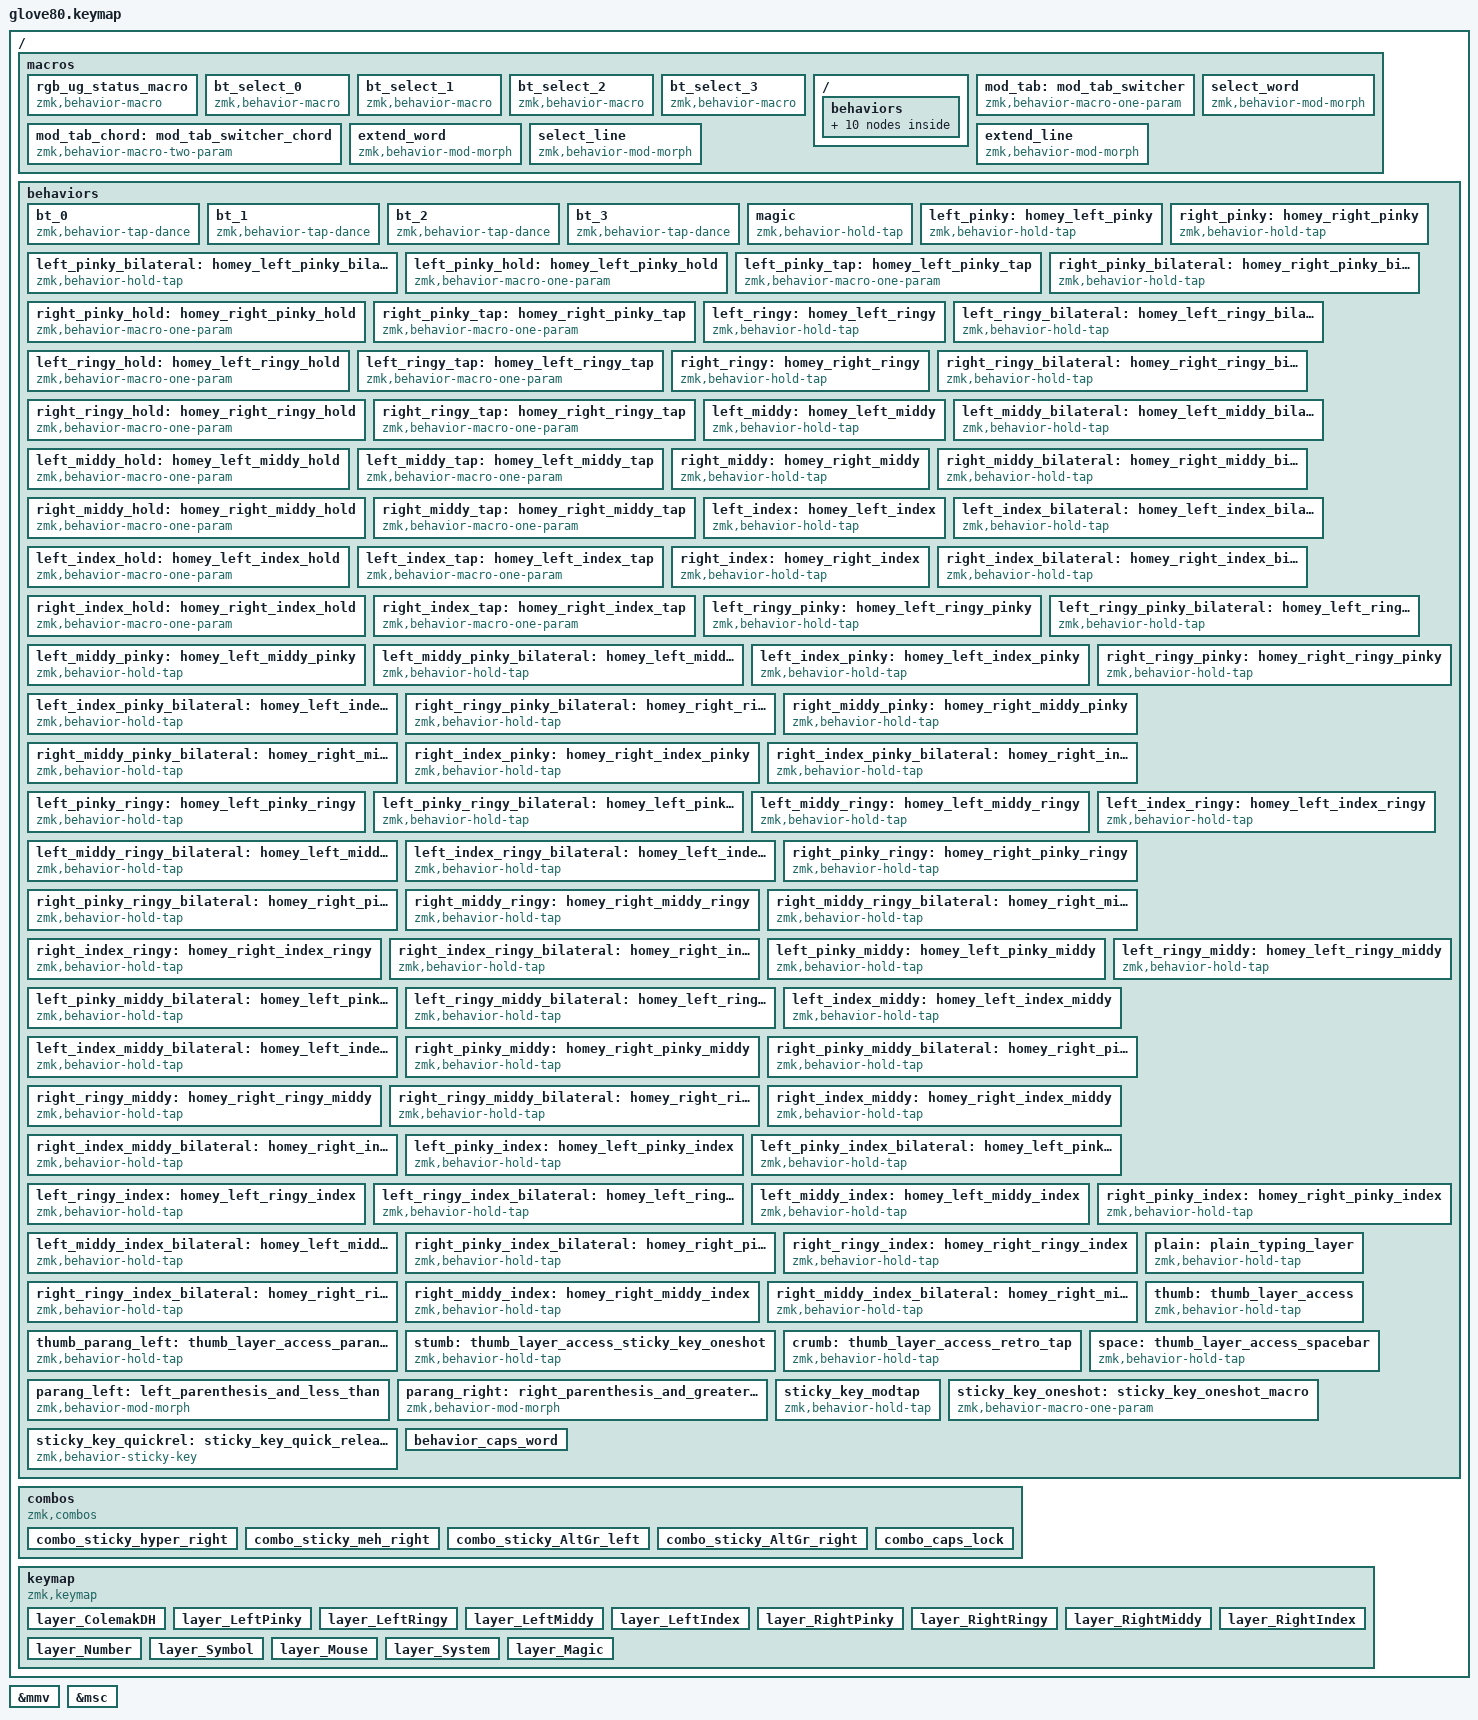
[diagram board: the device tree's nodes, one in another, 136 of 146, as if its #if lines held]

/*
 * Copyright (c) 2020 The ZMK Contributors
 * Copyright (c) 2023 Innaworks Development Limited, trading as MoErgo
 *
 * SPDX-License-Identifier: MIT
 */


/* THIS FILE WAS GENERATED BY GLOVE80 LAYOUT EDITOR
 *
 * This file was generated automatically. You may or may not want to
 * edit it directly.
 */

#include <behaviors.dtsi>
/* Include all behavior includes needed */
#include <dt-bindings/zmk/outputs.h>
#include <dt-bindings/zmk/keys.h>
#include <dt-bindings/zmk/bt.h>
#include <dt-bindings/zmk/rgb.h>

/* Automatically generated layer name #define */
#define LAYER_ColemakDH 0
#define LAYER_LeftPinky 1
#define LAYER_LeftRingy 2
#define LAYER_LeftMiddy 3
#define LAYER_LeftIndex 4
#define LAYER_RightPinky 5
#define LAYER_RightRingy 6
#define LAYER_RightMiddy 7
#define LAYER_RightIndex 8
#define LAYER_Number 9
#define LAYER_Symbol 10
#define LAYER_Mouse 11
#define LAYER_System 12
#define LAYER_Magic 13

/* Custom Device-tree */
//////////////////////////////////////////////////////////////////////////
//
// Mouse keys (keyboard mouse control) requires v24.12 firmware or newer:
// override the "HID_POINTING" setting to "y" in Advanced Configuration
// and then select "v24.12" firmware from the drop-down menu located at
// Glove80 Layout Editor > Settings > Advanced Settings > Firmware Version
//
// Alternatively, you can still use the older PR23 beta firmware for this:
// select "community.pr23.mouse-keys" from the drop-down menu located at
// Glove80 Layout Editor > Settings > Advanced Settings > Firmware Version
//
// - https://github.com/moergo-sc/zmk/pull/23
// - https://gist.github.com/krissen/dd27082e7ab0575619c7a31f4d2ec7ae
// - https://github.com/zmkfirmware/zmk/compare/main...urob:zmk:mouse-3.2
//
//////////////////////////////////////////////////////////////////////////

//
// MOUSE_MOTION_DELAY defines how long to wait (milliseconds) before starting
// to move the mouse pointer.
//
#ifndef MOUSE_MOTION_DELAY
#define MOUSE_MOTION_DELAY 0
#endif

//
// MOUSE_MOTION_ACCELERATION_EXPONENT sets how the mouse pointer accelerates:
//
// acceleration exponent 0: uniform speed
// acceleration exponent 1: uniform acceleration
// acceleration exponent 2: uniform jerk
//
#ifndef MOUSE_MOTION_ACCELERATION_EXPONENT
#define MOUSE_MOTION_ACCELERATION_EXPONENT 1
#endif

//
// MOUSE_MOTION_TIME_TO_MAXIMUM_SPEED defines how long to wait (milliseconds)
// before the mouse pointer speed is suddenly boosted to the maximum value.
//
#ifndef MOUSE_MOTION_TIME_TO_MAXIMUM_SPEED
#define MOUSE_MOTION_TIME_TO_MAXIMUM_SPEED 300
#endif

//
// MOUSE_MOTION_MAXIMUM_SPEED defines how quickly the mouse pointer can move.
//
#ifndef MOUSE_MOTION_MAXIMUM_SPEED
#define MOUSE_MOTION_MAXIMUM_SPEED 600
#endif

//
// MOUSE_SCROLL_DELAY defines how long to wait (milliseconds) before starting
// to move the mouse pointer.
//
#ifndef MOUSE_SCROLL_DELAY
#define MOUSE_SCROLL_DELAY 0
#endif

//
// MOUSE_SCROLL_ACCELERATION_EXPONENT sets how the mouse pointer accelerates:
//
// acceleration exponent 0: uniform speed
// acceleration exponent 1: uniform acceleration
// acceleration exponent 2: uniform jerk
//
#ifndef MOUSE_SCROLL_ACCELERATION_EXPONENT
#define MOUSE_SCROLL_ACCELERATION_EXPONENT 0
#endif

//
// MOUSE_SCROLL_TIME_TO_MAXIMUM_SPEED defines how long to wait (milliseconds)
// before the mouse pointer speed is suddenly boosted to the maximum value.
//
#ifndef MOUSE_SCROLL_TIME_TO_MAXIMUM_SPEED
#define MOUSE_SCROLL_TIME_TO_MAXIMUM_SPEED 300
#endif

//
// MOUSE_SCROLL_MAXIMUM_SPEED defines how quickly the mouse wheel can scroll.
//
#ifndef MOUSE_SCROLL_MAXIMUM_SPEED
#define MOUSE_SCROLL_MAXIMUM_SPEED 10
#endif

#if __has_include(<zmk/events/mouse_tick.h>) || ( \
  defined(MOERGO_FIRMWARE_VERSION_MAJOR) &&       \
  defined(MOERGO_FIRMWARE_VERSION_MINOR) && (     \
    MOERGO_FIRMWARE_VERSION_MAJOR == 24 &&        \
    MOERGO_FIRMWARE_VERSION_MINOR == 12 ||        \
    MOERGO_FIRMWARE_VERSION_MAJOR > 24            \
  )                                               \
)
  // ==== MOUSE-KEY <section begins> ====
  #define ZMK_MOUSE_DEFAULT_MOVE_VAL MOUSE_MOTION_MAXIMUM_SPEED
  #define ZMK_MOUSE_DEFAULT_SCRL_VAL MOUSE_SCROLL_MAXIMUM_SPEED
  #include <dt-bindings/zmk/mouse.h>
  &mmv {
    delay-ms = <MOUSE_MOTION_DELAY>;
    acceleration-exponent = <MOUSE_MOTION_ACCELERATION_EXPONENT>;
    time-to-max-speed-ms = <MOUSE_MOTION_TIME_TO_MAXIMUM_SPEED>;
  };
  &msc {
    delay-ms = <MOUSE_SCROLL_DELAY>;
    acceleration-exponent = <MOUSE_SCROLL_ACCELERATION_EXPONENT>;
    time-to-max-speed-ms = <MOUSE_SCROLL_TIME_TO_MAXIMUM_SPEED>;
  };
  // ==== MOUSE-KEY <section ends> =====
#else
  #define mkp none
  #define mmv none
  #define msc none
  #define LCLK
  #define MCLK
  #define RCLK
  #define MB1
  #define MB2
  #define MB3
  #define MB4
  #define MB5
  #define MB6
  #define MB7
  #define MB8
  #define MOVE_UP
  #define MOVE_DOWN
  #define MOVE_LEFT
  #define MOVE_RIGHT
  #define SCRL_UP
  #define SCRL_DOWN
  #define SCRL_LEFT
  #define SCRL_RIGHT
#endif

/ {
    macros {
        rgb_ug_status_macro: rgb_ug_status_macro {
            label = "RGB_UG_STATUS";
            compatible = "zmk,behavior-macro";
            #binding-cells = <0>;
            bindings
                = <&rgb_ug RGB_STATUS>;
        };
    };
};


/ {
#ifdef BT_DISC_CMD
    behaviors {
        bt_0: bt_0 {
            compatible = "zmk,behavior-tap-dance";
            label = "BT_0";
            #binding-cells = <0>;
            tapping-term-ms = <200>;
            bindings = <&bt_select_0>, <&bt BT_DISC 0>;
        };
        bt_1: bt_1 {
            compatible = "zmk,behavior-tap-dance";
            label = "BT_1";
            #binding-cells = <0>;
            tapping-term-ms = <200>;
            bindings = <&bt_select_1>, <&bt BT_DISC 1>;
        };
        bt_2: bt_2 {
            compatible = "zmk,behavior-tap-dance";
            label = "BT_2";
            #binding-cells = <0>;
            tapping-term-ms = <200>;
            bindings = <&bt_select_2>, <&bt BT_DISC 2>;
        };
        bt_3: bt_3 {
            compatible = "zmk,behavior-tap-dance";
            label = "BT_3";
            #binding-cells = <0>;
            tapping-term-ms = <200>;
            bindings = <&bt_select_3>, <&bt BT_DISC 3>;
        };
    };
    macros {
        bt_select_0: bt_select_0 {
            label = "BT_SELECT_0";
            compatible = "zmk,behavior-macro";
            #binding-cells = <0>;
            bindings
                = <&out OUT_BLE>,
                  <&bt BT_SEL 0>;
        };
        bt_select_1: bt_select_1 {
            label = "BT_SELECT_1";
            compatible = "zmk,behavior-macro";
            #binding-cells = <0>;
            bindings
                = <&out OUT_BLE>,
                  <&bt BT_SEL 1>;
        };
        bt_select_2: bt_select_2 {
            label = "BT_SELECT_2";
            compatible = "zmk,behavior-macro";
            #binding-cells = <0>;
            bindings
                = <&out OUT_BLE>,
                  <&bt BT_SEL 2>;
        };
        bt_select_3: bt_select_3 {
            label = "BT_SELECT_3";
            compatible = "zmk,behavior-macro";
            #binding-cells = <0>;
            bindings
                = <&out OUT_BLE>,
                  <&bt BT_SEL 3>;
        };
    };
#else
    macros {
        bt_0: bt_0 {
            label = "BT_0";
            compatible = "zmk,behavior-macro";
            #binding-cells = <0>;
            bindings
                = <&out OUT_BLE>,
                  <&bt BT_SEL 0>;
        };
        bt_1: bt_1 {
            label = "BT_1";
            compatible = "zmk,behavior-macro";
            #binding-cells = <0>;
            bindings
                = <&out OUT_BLE>,
                  <&bt BT_SEL 1>;
        };
        bt_2: bt_2 {
            label = "BT_2";
            compatible = "zmk,behavior-macro";
            #binding-cells = <0>;
            bindings
                = <&out OUT_BLE>,
                  <&bt BT_SEL 2>;
        };
        bt_3: bt_3 {
            label = "BT_3";
            compatible = "zmk,behavior-macro";
            #binding-cells = <0>;
            bindings
                = <&out OUT_BLE>,
                  <&bt BT_SEL 3>;
        };
    };
#endif
};

/ {
    behaviors {
        magic: magic {
            compatible = "zmk,behavior-hold-tap";
            label = "MAGIC_HOLD_TAP";
            #binding-cells = <2>;
            flavor = "tap-preferred";
            tapping-term-ms = <200>;
            bindings = <&mo>, <&rgb_ug_status_macro>;
        };
    };
};

/* #define for key positions */
#define POS_LH_T1 52
#define POS_LH_T2 53
#define POS_LH_T3 54
#define POS_LH_T4 69
#define POS_LH_T5 70
#define POS_LH_T6 71
#define POS_LH_C1R2 15
#define POS_LH_C1R3 27
#define POS_LH_C1R4 39
#define POS_LH_C1R5 51
#define POS_LH_C2R1 4
#define POS_LH_C2R2 14
#define POS_LH_C2R3 26
#define POS_LH_C2R4 38
#define POS_LH_C2R5 50
#define POS_LH_C2R6 68
#define POS_LH_C3R1 3
#define POS_LH_C3R2 13
#define POS_LH_C3R3 25
#define POS_LH_C3R4 37
#define POS_LH_C3R5 49
#define POS_LH_C3R6 67
#define POS_LH_C4R1 2
#define POS_LH_C4R2 12
#define POS_LH_C4R3 24
#define POS_LH_C4R4 36
#define POS_LH_C4R5 48
#define POS_LH_C4R6 66
#define POS_LH_C5R1 1
#define POS_LH_C5R2 11
#define POS_LH_C5R3 23
#define POS_LH_C5R4 35
#define POS_LH_C5R5 47
#define POS_LH_C5R6 65
#define POS_LH_C6R1 0
#define POS_LH_C6R2 10
#define POS_LH_C6R3 22
#define POS_LH_C6R4 34
#define POS_LH_C6R5 46
#define POS_LH_C6R6 64
#define POS_RH_T1 57
#define POS_RH_T2 56
#define POS_RH_T3 55
#define POS_RH_T4 74
#define POS_RH_T5 73
#define POS_RH_T6 72
#define POS_RH_C1R2 16
#define POS_RH_C1R3 28
#define POS_RH_C1R4 40
#define POS_RH_C1R5 58
#define POS_RH_C2R1 5
#define POS_RH_C2R2 17
#define POS_RH_C2R3 29
#define POS_RH_C2R4 41
#define POS_RH_C2R5 59
#define POS_RH_C2R6 75
#define POS_RH_C3R1 6
#define POS_RH_C3R2 18
#define POS_RH_C3R3 30
#define POS_RH_C3R4 42
#define POS_RH_C3R5 60
#define POS_RH_C3R6 76
#define POS_RH_C4R1 7
#define POS_RH_C4R2 19
#define POS_RH_C4R3 31
#define POS_RH_C4R4 43
#define POS_RH_C4R5 61
#define POS_RH_C4R6 77
#define POS_RH_C5R1 8
#define POS_RH_C5R2 20
#define POS_RH_C5R3 32
#define POS_RH_C5R4 44
#define POS_RH_C5R5 62
#define POS_RH_C5R6 78
#define POS_RH_C6R1 9
#define POS_RH_C6R2 21
#define POS_RH_C6R3 33
#define POS_RH_C6R4 45
#define POS_RH_C6R5 63
#define POS_RH_C6R6 79

/* Custom Defined Behaviors */
/ {
// NOTE: Use the many #define settings below to customize this keymap!
#define OPERATING_SYSTEM 'L' // choose 'L'inux, 'M'acOS, or 'W'indows
#define ENFORCE_BILATERAL    // cancels single-handed home row mod+tap
#define SPACE_FORGIVENESS    // allow lingering taps on the space bar
//#define THUMB_FORGIVENESS  // allow lingering taps on the thumb keys
//#define SHIFT_FORGIVENESS  // requires 24.08-beta1 or newer firmware
#define WORLD_USE_COMPOSE    // use native Compose in place of Unicode
//#define WORLD_HOST_AZERTY  // host computer is set to AZERTY locale
//#define WORLD_SHIFT_NUMBER // apply Shift to type number row digits
// TIP: Add more setting overrides here instead of editing them below.

//////////////////////////////////////////////////////////////////////////////
//
// Sunaku's Keymap v40 -- "Glorious Engrammer"
// - https://github.com/sunaku/glove80-keymaps
//
//////////////////////////////////////////////////////////////////////////////

//
// OPERATING_SYSTEM defines which operating system you intend to use
// with this keymap, because shortcuts vary across operating systems.
//
// - https://zmk.dev/docs/codes
// - https://en.wikipedia.org/wiki/Table_of_keyboard_shortcuts
//
// This setting also affects the UNICODE() function defined below, as
// each OS has different shortcuts for typing Unicode hex characters.
//
// NOTE: You may need to enable Unicode hexadecimal input in your OS:
// - (macOS) https://uknowit.uwgb.edu/page.php?id=22623
//     and   https://github.com/ldanet/unicode-hex-input-fix
// - (Linux) https://help.ubuntu.com/stable/ubuntu-help/tips-specialchars.html.en#ctrlshiftu
// - (Windows) https://github.com/samhocevar/wincompose
//
// Specifically, Windows users should be running the WinCompose tool,
// which lets you type Unicode characters via hexadecimal codepoints.
//
#ifndef OPERATING_SYSTEM
#define OPERATING_SYSTEM 'L' // linux
//#define OPERATING_SYSTEM 'M' // macos
//#define OPERATING_SYSTEM 'W' // windows
#endif
#if OPERATING_SYSTEM == 'M'
  #define _C      LG
  #define _A_TAB  LGUI
  #define _G_TAB  LALT
  #define _REDO   _C(LS(Z))
  #define _POWER  K_POWER
  #define _W      LA
  #define _HOME   _C(LEFT)
  #define _END    _C(RIGHT)
#else
  #define _C      LC
  #define _A_TAB  LALT
  #define _G_TAB  LGUI
  #define _REDO   _C(Y)
  #define _POWER  C_POWER
  #define _W      _C
  #define _HOME   HOME
  #define _END    END
#endif
#define _SLEEP      C_SLEEP
#if OPERATING_SYSTEM == 'W'
  #define _LOCK   LG(L)
#elif OPERATING_SYSTEM == 'M'
  #define _LOCK   _C(LC(Q))
#elif OPERATING_SYSTEM == 'L'
  #define _LOCK   K_LOCK
#endif
#define _UNDO       _C(Z)
#define _CUT        _C(X)
#define _COPY       _C(C)
#define _PASTE      _C(V)
#define _FIND       _C(F)
#define _FIND_NEXT  _C(G)
#define _FIND_PREV  _C(LS(G))

//
// USE_NUMPAD_KEYCODES puts `KP_*` keycodes into the Number layer.
//
#ifdef USE_NUMPAD_KEYCODES
#define _KP_N0 KP_N0
#define _KP_N1 KP_N1
#define _KP_N2 KP_N2
#define _KP_N3 KP_N3
#define _KP_N4 KP_N4
#define _KP_N5 KP_N5
#define _KP_N6 KP_N6
#define _KP_N7 KP_N7
#define _KP_N8 KP_N8
#define _KP_N9 KP_N9
#define _KP_PLUS KP_PLUS
#define _KP_MINUS KP_MINUS
#define _KP_ASTERISK KP_ASTERISK
#define _KP_SLASH KP_SLASH
#define _KP_COMMA KP_COMMA
#define _KP_DOT KP_DOT
#define _KP_EQUAL KP_EQUAL
#define _KP_ENTER KP_ENTER
#else
#define _KP_N0 N0
#define _KP_N1 N1
#define _KP_N2 N2
#define _KP_N3 N3
#define _KP_N4 N4
#define _KP_N5 N5
#define _KP_N6 N6
#define _KP_N7 N7
#define _KP_N8 N8
#define _KP_N9 N9
#define _KP_PLUS PLUS
#define _KP_MINUS MINUS
#define _KP_ASTERISK ASTERISK
#define _KP_SLASH SLASH
#define _KP_COMMA COMMA
#define _KP_DOT DOT
#define _KP_EQUAL EQUAL
#define _KP_ENTER ENTER
#endif

//
// Keymap specific knowledge of the base layer's alpha + ZMK layout
//
#if defined(LAYER_ColemakDH) && LAYER_ColemakDH == 0
#define KEY_LH_C6R1 UP
#define KEY_LH_C5R1 DOWN
#define KEY_LH_C4R1 A
#define KEY_LH_C3R1 B
#define KEY_LH_C2R1 C
#define KEY_RH_C2R1 D
#define KEY_RH_C3R1 E
#define KEY_RH_C4R1 F
#define KEY_RH_C5R1 LEFT
#define KEY_RH_C6R1 RIGHT
#define KEY_LH_C6R2 EQUAL
#define KEY_LH_C5R2 N1
#define KEY_LH_C4R2 N2
#define KEY_LH_C3R2 N3
#define KEY_LH_C2R2 N4
#define KEY_LH_C1R2 N5
#define KEY_RH_C1R2 N6
#define KEY_RH_C2R2 N7
#define KEY_RH_C3R2 N8
#define KEY_RH_C4R2 N9
#define KEY_RH_C5R2 N0
#define KEY_RH_C6R2 MINUS
#define KEY_LH_C6R3 GRAVE
#define KEY_LH_C5R3 Q
#define KEY_LH_C4R3 W
#define KEY_LH_C3R3 F
#define KEY_LH_C2R3 P
#define KEY_LH_C1R3 B
#define KEY_RH_C1R3 J
#define KEY_RH_C2R3 L
#define KEY_RH_C3R3 U
#define KEY_RH_C4R3 Y
#define KEY_RH_C5R3 SEMI
#define KEY_RH_C6R3 BSLH
#define KEY_LH_C6R4 CAPS
#define KEY_LH_C5R4 A
#define KEY_LH_C4R4 R
#define KEY_LH_C3R4 S
#define KEY_LH_C2R4 T
#define KEY_LH_C1R4 G
#define KEY_RH_C1R4 M
#define KEY_RH_C2R4 N
#define KEY_RH_C3R4 E
#define KEY_RH_C4R4 I
#define KEY_RH_C5R4 O
#define KEY_RH_C6R4 SQT
#define KEY_LH_C6R5 LSFT
#define KEY_LH_C5R5 Z
#define KEY_LH_C4R5 X
#define KEY_LH_C3R5 C
#define KEY_LH_C2R5 D
#define KEY_LH_C1R5 V
#define KEY_LH_T1 ESC
#define KEY_LH_T2 LSFT
#define KEY_LH_T3 0
#define KEY_RH_T3 0
#define KEY_RH_T2 RSFT
#define KEY_RH_T1 ENTER
#define KEY_RH_C1R5 K
#define KEY_RH_C2R5 H
#define KEY_RH_C3R5 COMMA
#define KEY_RH_C4R5 DOT
#define KEY_RH_C5R5 FSLH
#define KEY_RH_C6R5 RSFT
#define KEY_LH_C6R6 0
#define KEY_LH_C5R6 HOME
#define KEY_LH_C4R6 PG_UP
#define KEY_LH_C3R6 PG_DN
#define KEY_LH_C2R6 END
#define KEY_LH_T4 BACKSPACE
#define KEY_LH_T5 DELETE
#define KEY_LH_T6 0
#define KEY_RH_T6 0
#define KEY_RH_T5 TAB
#define KEY_RH_T4 SPACE
#define KEY_RH_C2R6 LPAR
#define KEY_RH_C3R6 LBKT
#define KEY_RH_C4R6 RBKT
#define KEY_RH_C5R6 RPAR
#define KEY_RH_C6R6 0
#endif

combos {
  compatible = "zmk,combos";

  //
  // COMBO_FIRING_DECAY defines how much time you have left (milliseconds)
  // after pressing the first key in a ZMK combo to finish the whole chord.
  //
  #ifndef COMBO_FIRING_DECAY
  #define COMBO_FIRING_DECAY 50
  #endif

  combo_sticky_hyper_right {
    timeout-ms = <COMBO_FIRING_DECAY>;
    key-positions = <POS_RH_T1 POS_RH_T4>;
    bindings = <&sk LG(LA(LC(LSHFT)))>;
    layers = <0 1 2 3 4 5 6 7 8 9 10>;
  };

  combo_sticky_meh_right {
    timeout-ms = <COMBO_FIRING_DECAY>;
    key-positions = <POS_RH_T4 POS_RH_T5>;
    bindings = <&sk LA(LC(LSHFT))>;
    layers = <0 1 2 3 4 5 6 7 8 9 10>;
  };

  combo_sticky_AltGr_left {
    timeout-ms = <COMBO_FIRING_DECAY>;
    key-positions = <POS_LH_T2 POS_LH_T5>;
    bindings = <&sk RALT>;
    layers = <0 1 2 3 4 5 6 7 8 9 10>;
  };

  combo_sticky_AltGr_right {
    timeout-ms = <COMBO_FIRING_DECAY>;
    key-positions = <POS_RH_T2 POS_RH_T5>;
    bindings = <&sk RALT>;
    layers = <0 1 2 3 4 5 6 7 8 9 10>;
  };

  combo_caps_lock {
    timeout-ms = <COMBO_FIRING_DECAY>;
    key-positions = <POS_LH_T6 POS_RH_T6>;
    bindings = <&kp CAPSLOCK>;
    layers = <0 1 2 3 4 5 6 7 8 9 10>;
  };

};

behaviors {

  //////////////////////////////////////////////////////////////////////////
  //
  // Miryoku layers and home row mods (ported from my QMK endgame)
  // - https://sunaku.github.io/home-row-mods.html#porting-to-zmk
  // - https://github.com/urob/zmk-config#timeless-homerow-mods
  //
  //////////////////////////////////////////////////////////////////////////

  //
  // TAPPING_RESOLUTION specifies the maximum speed at which the keyboard
  // confuses your taps as being holds when you type on home row mod keys.
  // When you lower this value, the same confusion should still occur; but
  // when you raise this value, you should be able to type normally again.
  //
  #ifndef TAPPING_RESOLUTION
  #define TAPPING_RESOLUTION 150
  #endif

  //
  // ENFORCE_BILATERAL cancels out single-handed home row mods activation by
  // releasing any currently pressed mods and replacing them with plain taps.
  //
  // NOTE: You may still encounter "flashing mods" where an operating system
  // action is triggered by the release of mods, such as LGUI which launches
  // the Windows Start Menu and LALT which opens the Microsoft Office Ribbon.
  //
  //#define ENFORCE_BILATERAL

  //
  // SHIFT_FORGIVENESS taps when home row shift is merely held and released,
  // without any other key having been tapped while the shift was held down.
  // For example, suppose you hold a home row shift key and, before pressing
  // another key, you suddenly decide that you don't want the shift anymore:
  //
  // <1> If this setting is enabled, the underlying tap behavior is triggered
  //     to type a single character when you release that home row shift key.
  //
  // <2> Otherwise, nothing happens when you release that home row shift key.
  //
  // This requires the "hold-while-undecided" ZMK feature in a beta firmware:
  // please select "v24.08-beta1" or newer from the drop-down menu located at
  // Glove80 Layout Editor > Settings > Advanced Settings > Firmware Version.
  //
  // CAUTION: This can interfere with mod-click mouse usage where you hold a
  // home row shift key and perform mouse actions (move, click, drag & drop):
  // when you release that home row shift key, its underlying character would
  // be typed, potentially triggering an unexpected action on your selection!
  // To prevent the underlying character from being typed, press another key
  // (such as a dedicated shift key, a neighboring home row mod key, or even
  // a layer access key) before you release the original home row shift key.
  //
  // NOTE: You may potentially encounter "flashing mods" where an application
  // or operating system action is triggered by a standalone tap of a shift,
  // but this is unlikely as people regularly tap shift without consequence.
  //
  //#define SHIFT_FORGIVENESS

  //
  // THUMB_FORGIVENESS taps when a thumb layer access key is merely held and
  // released, without any other key having been tapped while thumb was held.
  // For example, suppose you hold the cursor layer key and, before pressing
  // another key, you suddenly decide that you don't want the layer anymore:
  //
  // <1> If this setting is enabled, the underlying tap behavior is triggered
  //     to type a single character when you release that layer access key.
  //
  // <2> Otherwise, nothing happens when you release that layer access key.
  //
  // NOTE: This setting interferes with (and effectively disables) per-key
  // RGB indicators (PR30) for layers accessed via thumb layer access keys.
  //
  //#define THUMB_FORGIVENESS

  //
  // SPACE_FORGIVENESS taps when the symbol layer access key is merely held
  // and released, without any symbol been tapped while the access was held.
  // For example, suppose you hold the symbol layer key and, before pressing
  // another key, you suddenly decide that you don't want the layer anymore:
  //
  // <1> If this setting is enabled, the underlying tap behavior is triggered
  //     to type a single character when you release that layer access key.
  //
  // <2> Otherwise, nothing happens when you release that layer access key.
  //
  // NOTE: This setting interferes with (and effectively disables) per-key
  // RGB indicators (PR30) for layers accessed via thumb layer access keys.
  //
  //#define SPACE_FORGIVENESS

  //
  // The *_FINGER_MOD specify which modifiers are used by home row mod keys.
  // Here, we use Miryoku's "GACS" (Win, Alt, Ctrl, Shift) order by default,
  // unless OPERATING_SYSTEM is macOS, in which case Win & Ctrl are swapped,
  // unless MACOS_USE_GACS is also defined to suppress that Win & Ctrl swap.
  //
  #ifndef PINKY_FINGER_MOD
    #if OPERATING_SYSTEM == 'M' && !defined(MACOS_USE_GACS)
      #define PINKY_FINGER_MOD LCTL
    #else
      #define PINKY_FINGER_MOD LGUI
    #endif
  #endif
  #ifndef RINGY_FINGER_MOD
  #define RINGY_FINGER_MOD LALT
  #endif
  #ifndef MIDDY_FINGER_MOD
    #if OPERATING_SYSTEM == 'M' && !defined(MACOS_USE_GACS)
      #define MIDDY_FINGER_MOD LGUI
    #else
      #define MIDDY_FINGER_MOD LCTL
    #endif
  #endif
  #ifndef INDEX_FINGER_MOD
  #define INDEX_FINGER_MOD LSFT
  #endif
  //
  // The following settings let you configure mods individually, per finger:
  //
  #ifndef LEFT_PINKY_MOD
  #define LEFT_PINKY_MOD PINKY_FINGER_MOD
  #endif
  #ifndef RIGHT_PINKY_MOD
  #define RIGHT_PINKY_MOD PINKY_FINGER_MOD
  #endif
  #ifndef LEFT_RINGY_MOD
  #define LEFT_RINGY_MOD RINGY_FINGER_MOD
  #endif
  #ifndef RIGHT_RINGY_MOD
  #define RIGHT_RINGY_MOD RINGY_FINGER_MOD
  #endif
  #ifndef LEFT_MIDDY_MOD
  #define LEFT_MIDDY_MOD MIDDY_FINGER_MOD
  #endif
  #ifndef RIGHT_MIDDY_MOD
  #define RIGHT_MIDDY_MOD MIDDY_FINGER_MOD
  #endif
  #ifndef LEFT_INDEX_MOD
  #define LEFT_INDEX_MOD INDEX_FINGER_MOD
  #endif
  #ifndef RIGHT_INDEX_MOD
  #define RIGHT_INDEX_MOD INDEX_FINGER_MOD
  #endif

  //
  // HOMEY_HOLDING_TYPE defines the flavor of ZMK hold-tap behavior to use
  // for the pinky, ring, and middle fingers (which are assigned to Super,
  // Alt, and Ctrl respectively in the Miryoku system) on home row keys.
  //
  #ifndef HOMEY_HOLDING_TYPE
  #define HOMEY_HOLDING_TYPE "tap-preferred"
  #endif

  //
  // HOMEY_HOLDING_TIME defines how long you need to hold (milliseconds)
  // home row mod keys in order to send their modifiers to the computer
  // (i.e. "register" them) for mod-click mouse usage (e.g. Ctrl-Click).
  //
  #ifndef HOMEY_HOLDING_TIME
  #define HOMEY_HOLDING_TIME (TAPPING_RESOLUTION + 90)
  #endif
  #ifndef INDEX_HOLDING_TIME
  #define INDEX_HOLDING_TIME (TAPPING_RESOLUTION + 20)
  #endif
  #ifndef MIDDY_HOLDING_TIME
  #define MIDDY_HOLDING_TIME (TAPPING_RESOLUTION + 60)
  #endif
  #ifndef RINGY_HOLDING_TIME
  #define RINGY_HOLDING_TIME (TAPPING_RESOLUTION + 90)
  #endif
  #ifndef PINKY_HOLDING_TIME
  #define PINKY_HOLDING_TIME (TAPPING_RESOLUTION + 110)
  #endif

  //
  // HOMEY_STREAK_DECAY defines how long you need to wait (milliseconds)
  // after typing before you can use home row mods again.  It prevents
  // unintended activation of home row mods when you're actively typing.
  //
  #ifndef HOMEY_STREAK_DECAY
  #define HOMEY_STREAK_DECAY TAPPING_RESOLUTION
  #endif

  //
  // CHORD_HOLDING_TYPE defines the flavor of ZMK hold-tap behavior to use
  // for chorded home row mods (secondary keypresses in multi-mod chords).
  //
  #ifndef CHORD_HOLDING_TYPE
  #define CHORD_HOLDING_TYPE HOMEY_HOLDING_TYPE
  #endif

  //
  // CHORD_HOLDING_TIME defines how long you need to hold (milliseconds)
  // home row mod keys in order to send their modifiers to the computer
  // (i.e. "register" them) for mod-click mouse usage (e.g. Ctrl-Click).
  // This is specifically for secondary keypresses in multi-mod chords.
  //
  #ifndef CHORD_HOLDING_TIME
  #define CHORD_HOLDING_TIME TAPPING_RESOLUTION
  #endif

  //
  // CHORD_STREAK_DECAY defines how long you need to wait (milliseconds)
  // after typing before you can use home row mods again.  It prevents
  // unintended activation of home row mods when you're actively typing
  // This is specifically for secondary keypresses in multi-mod chords.
  //
  #ifndef CHORD_STREAK_DECAY
  #define CHORD_STREAK_DECAY HOMEY_STREAK_DECAY
  #endif

  //
  // INDEX_HOLDING_TYPE defines the flavor of ZMK hold-tap behavior to use
  // for index fingers (which Miryoku assigns to Shift) on home row keys.
  //
  // NOTE: The "tap-preferred" flavor of ZMK hold-tap for index finger keys
  // allows faster activation of the Shift modifier (without having to wait
  // for the modified key to be released as the "balanced" flavor requires).
  //
  #ifndef INDEX_HOLDING_TYPE
  #define INDEX_HOLDING_TYPE "tap-preferred"
  #endif

  //
  // INDEX_STREAK_DECAY defines how long you need to wait (milliseconds)
  // after typing before you can use home row mods again.  It prevents
  // unintended activation of home row mods when you're actively typing.
  //
  #ifndef INDEX_STREAK_DECAY
  #define INDEX_STREAK_DECAY (TAPPING_RESOLUTION - 50)
  #endif

  //
  // PLAIN_HOLDING_TYPE defines the flavor of ZMK hold-tap behavior to use
  // for index fingers (which Miryoku assigns to Shift) on home row keys.
  //
  // NOTE: The "tap-preferred" flavor of ZMK hold-tap for index finger keys
  // allows faster activation of the Shift modifier (without having to wait
  // for the modified key to be released as the "balanced" flavor requires).
  //
  #ifndef PLAIN_HOLDING_TYPE
  #define PLAIN_HOLDING_TYPE INDEX_HOLDING_TYPE
  #endif

  //
  // PLAIN_HOLDING_TIME defines how long you need to hold (milliseconds)
  // index finger keys in order to send their modifiers to the computer
  // (i.e. "register" them) for mod-click mouse usage (e.g. Shift-Click).
  //
  #ifndef PLAIN_HOLDING_TIME
  #define PLAIN_HOLDING_TIME (TAPPING_RESOLUTION + 50)
  #endif

  //
  // PLAIN_STREAK_DECAY defines how long you need to wait (milliseconds)
  // after typing before you can use home row mods again.  It prevents
  // unintended activation of home row mods when you're actively typing.
  //
  #ifndef PLAIN_STREAK_DECAY
  #define PLAIN_STREAK_DECAY HOMEY_STREAK_DECAY
  #endif

  //
  // THUMB_HOLDING_TYPE defines the flavor of ZMK hold-tap behavior to use
  // for the thumbs (which are assigned to 6 layers in the Miryoku system).
  //
  // NOTE: The "balanced" flavor of ZMK hold-tap provides instant modifier
  // activation for the symbol layer (if the tapped symbol key is released
  // while the thumb layer key is still held down) for quicker programming.
  //
  #ifndef THUMB_HOLDING_TYPE
  #define THUMB_HOLDING_TYPE "balanced"
  #endif

  //
  // THUMB_HOLDING_TIME defines how long you need to hold (milliseconds)
  // a thumb key to activate a layer.  Shorter holds are treated as taps.
  //
  #ifndef THUMB_HOLDING_TIME
  #define THUMB_HOLDING_TIME (TAPPING_RESOLUTION + 50)
  #endif

  //
  // SPACE_HOLDING_TYPE defines the flavor of ZMK hold-tap behavior to use
  // for spacebar (assigned to the right thumb's home position by default).
  //
  #ifndef SPACE_HOLDING_TYPE
  #define SPACE_HOLDING_TYPE THUMB_HOLDING_TYPE
  #endif

  //
  // SPACE_HOLDING_TIME defines how long you need to hold (milliseconds)
  // the space thumb key to activate.  Shorter holds are treated as taps.
  //
  #ifndef SPACE_HOLDING_TIME
  #define SPACE_HOLDING_TIME (TAPPING_RESOLUTION + 20)
  #endif

  //
  // Glove80 key positions index for positional hold-tap
  // - https://discord.com/channels/877392805654306816/937645688244826154/1066713913351221248
  // - https://media.discordapp.net/attachments/937645688244826154/1066713913133121556/image.png
  //
  // |------------------------|------------------------|
  // | LEFT_HAND_KEYS         |        RIGHT_HAND_KEYS |
  // |                        |                        |
  // |  0  1  2  3  4         |          5  6  7  8  9 |
  // | 10 11 12 13 14 15      |      16 17 18 19 20 21 |
  // | 22 23 24 25 26 27      |      28 29 30 31 32 33 |
  // | 34 35 36 37 38 39      |      40 41 42 43 44 45 |
  // | 46 47 48 49 50 51      |      58 59 60 61 62 63 |
  // | 64 65 66 67 68         |         75 76 77 78 79 |
  // |                69 52   |   57 74                |
  // |                 70 53  |  56 73                 |
  // |                  71 54 | 55 72                  |
  // |------------------------|------------------------|
  //
  #define LEFT_HAND_KEYS      \
          0  1  2  3  4       \
         10 11 12 13 14 15    \
         22 23 24 25 26 27    \
         34 35 36 37 38 39    \
         46 47 48 49 50 51    \
         64 65 66 67 68
  #define RIGHT_HAND_KEYS     \
                                           5  6  7  8  9 \
                                       16 17 18 19 20 21 \
                                       28 29 30 31 32 33 \
                                       40 41 42 43 44 45 \
                                       58 59 60 61 62 63 \
                                          75 76 77 78 79
  #define THUMB_KEYS          \
                        69 52       57 74                \
                         70 53     56 73                 \
                          71 54   55 72

  #define LEFT_PINKY_KEY  KEY_LH_C5R4
  #define LEFT_RINGY_KEY  KEY_LH_C4R4
  #define LEFT_MIDDY_KEY  KEY_LH_C3R4
  #define LEFT_INDEX_KEY  KEY_LH_C2R4

  #define RIGHT_PINKY_KEY KEY_RH_C5R4
  #define RIGHT_RINGY_KEY KEY_RH_C4R4
  #define RIGHT_MIDDY_KEY KEY_RH_C3R4
  #define RIGHT_INDEX_KEY KEY_RH_C2R4

  //
  // Home row mods with bilateral combinations support
  //
  #ifndef PINKY_HOLDING_TYPE
  #define PINKY_HOLDING_TYPE HOMEY_HOLDING_TYPE
  #endif
  #ifndef PINKY_CHORD_HOLDING_TYPE
  #define PINKY_CHORD_HOLDING_TYPE CHORD_HOLDING_TYPE
  #endif
  #ifndef LEFT_PINKY_CHORD_HOLDING_TYPE
  #define LEFT_PINKY_CHORD_HOLDING_TYPE PINKY_CHORD_HOLDING_TYPE
  #endif
  #ifndef RIGHT_PINKY_CHORD_HOLDING_TYPE
  #define RIGHT_PINKY_CHORD_HOLDING_TYPE PINKY_CHORD_HOLDING_TYPE
  #endif
  #ifndef PINKY_HOLDING_TIME
  #define PINKY_HOLDING_TIME HOMEY_HOLDING_TIME
  #endif
  #ifndef PINKY_CHORD_HOLDING_TIME
  #define PINKY_CHORD_HOLDING_TIME CHORD_HOLDING_TIME
  #endif
  #ifndef LEFT_PINKY_CHORD_HOLDING_TIME
  #define LEFT_PINKY_CHORD_HOLDING_TIME PINKY_CHORD_HOLDING_TIME
  #endif
  #ifndef RIGHT_PINKY_CHORD_HOLDING_TIME
  #define RIGHT_PINKY_CHORD_HOLDING_TIME PINKY_CHORD_HOLDING_TIME
  #endif
  #ifndef PINKY_STREAK_DECAY
  #define PINKY_STREAK_DECAY HOMEY_STREAK_DECAY
  #endif
  #ifndef PINKY_CHORD_STREAK_DECAY
  #define PINKY_CHORD_STREAK_DECAY CHORD_STREAK_DECAY
  #endif
  #ifndef LEFT_PINKY_CHORD_STREAK_DECAY
  #define LEFT_PINKY_CHORD_STREAK_DECAY PINKY_CHORD_STREAK_DECAY
  #endif
  #ifndef RIGHT_PINKY_CHORD_STREAK_DECAY
  #define RIGHT_PINKY_CHORD_STREAK_DECAY PINKY_CHORD_STREAK_DECAY
  #endif
  #ifndef RINGY_HOLDING_TYPE
  #define RINGY_HOLDING_TYPE HOMEY_HOLDING_TYPE
  #endif
  #ifndef RINGY_CHORD_HOLDING_TYPE
  #define RINGY_CHORD_HOLDING_TYPE CHORD_HOLDING_TYPE
  #endif
  #ifndef LEFT_RINGY_CHORD_HOLDING_TYPE
  #define LEFT_RINGY_CHORD_HOLDING_TYPE RINGY_CHORD_HOLDING_TYPE
  #endif
  #ifndef RIGHT_RINGY_CHORD_HOLDING_TYPE
  #define RIGHT_RINGY_CHORD_HOLDING_TYPE RINGY_CHORD_HOLDING_TYPE
  #endif
  #ifndef RINGY_HOLDING_TIME
  #define RINGY_HOLDING_TIME HOMEY_HOLDING_TIME
  #endif
  #ifndef RINGY_CHORD_HOLDING_TIME
  #define RINGY_CHORD_HOLDING_TIME CHORD_HOLDING_TIME
  #endif
  #ifndef LEFT_RINGY_CHORD_HOLDING_TIME
  #define LEFT_RINGY_CHORD_HOLDING_TIME RINGY_CHORD_HOLDING_TIME
  #endif
  #ifndef RIGHT_RINGY_CHORD_HOLDING_TIME
  #define RIGHT_RINGY_CHORD_HOLDING_TIME RINGY_CHORD_HOLDING_TIME
  #endif
  #ifndef RINGY_STREAK_DECAY
  #define RINGY_STREAK_DECAY HOMEY_STREAK_DECAY
  #endif
  #ifndef RINGY_CHORD_STREAK_DECAY
  #define RINGY_CHORD_STREAK_DECAY CHORD_STREAK_DECAY
  #endif
  #ifndef LEFT_RINGY_CHORD_STREAK_DECAY
  #define LEFT_RINGY_CHORD_STREAK_DECAY RINGY_CHORD_STREAK_DECAY
  #endif
  #ifndef RIGHT_RINGY_CHORD_STREAK_DECAY
  #define RIGHT_RINGY_CHORD_STREAK_DECAY RINGY_CHORD_STREAK_DECAY
  #endif
  #ifndef MIDDY_HOLDING_TYPE
  #define MIDDY_HOLDING_TYPE HOMEY_HOLDING_TYPE
  #endif
  #ifndef MIDDY_CHORD_HOLDING_TYPE
  #define MIDDY_CHORD_HOLDING_TYPE CHORD_HOLDING_TYPE
  #endif
  #ifndef LEFT_MIDDY_CHORD_HOLDING_TYPE
  #define LEFT_MIDDY_CHORD_HOLDING_TYPE MIDDY_CHORD_HOLDING_TYPE
  #endif
  #ifndef RIGHT_MIDDY_CHORD_HOLDING_TYPE
  #define RIGHT_MIDDY_CHORD_HOLDING_TYPE MIDDY_CHORD_HOLDING_TYPE
  #endif
  #ifndef MIDDY_HOLDING_TIME
  #define MIDDY_HOLDING_TIME HOMEY_HOLDING_TIME
  #endif
  #ifndef MIDDY_CHORD_HOLDING_TIME
  #define MIDDY_CHORD_HOLDING_TIME CHORD_HOLDING_TIME
  #endif
  #ifndef LEFT_MIDDY_CHORD_HOLDING_TIME
  #define LEFT_MIDDY_CHORD_HOLDING_TIME MIDDY_CHORD_HOLDING_TIME
  #endif
  #ifndef RIGHT_MIDDY_CHORD_HOLDING_TIME
  #define RIGHT_MIDDY_CHORD_HOLDING_TIME MIDDY_CHORD_HOLDING_TIME
  #endif
  #ifndef MIDDY_STREAK_DECAY
  #define MIDDY_STREAK_DECAY HOMEY_STREAK_DECAY
  #endif
  #ifndef MIDDY_CHORD_STREAK_DECAY
  #define MIDDY_CHORD_STREAK_DECAY CHORD_STREAK_DECAY
  #endif
  #ifndef LEFT_MIDDY_CHORD_STREAK_DECAY
  #define LEFT_MIDDY_CHORD_STREAK_DECAY MIDDY_CHORD_STREAK_DECAY
  #endif
  #ifndef RIGHT_MIDDY_CHORD_STREAK_DECAY
  #define RIGHT_MIDDY_CHORD_STREAK_DECAY MIDDY_CHORD_STREAK_DECAY
  #endif
  #ifndef INDEX_HOLDING_TYPE
  #define INDEX_HOLDING_TYPE HOMEY_HOLDING_TYPE
  #endif
  #ifndef INDEX_CHORD_HOLDING_TYPE
  #define INDEX_CHORD_HOLDING_TYPE CHORD_HOLDING_TYPE
  #endif
  #ifndef LEFT_INDEX_CHORD_HOLDING_TYPE
  #define LEFT_INDEX_CHORD_HOLDING_TYPE INDEX_CHORD_HOLDING_TYPE
  #endif
  #ifndef RIGHT_INDEX_CHORD_HOLDING_TYPE
  #define RIGHT_INDEX_CHORD_HOLDING_TYPE INDEX_CHORD_HOLDING_TYPE
  #endif
  #ifndef INDEX_HOLDING_TIME
  #define INDEX_HOLDING_TIME HOMEY_HOLDING_TIME
  #endif
  #ifndef INDEX_CHORD_HOLDING_TIME
  #define INDEX_CHORD_HOLDING_TIME CHORD_HOLDING_TIME
  #endif
  #ifndef LEFT_INDEX_CHORD_HOLDING_TIME
  #define LEFT_INDEX_CHORD_HOLDING_TIME INDEX_CHORD_HOLDING_TIME
  #endif
  #ifndef RIGHT_INDEX_CHORD_HOLDING_TIME
  #define RIGHT_INDEX_CHORD_HOLDING_TIME INDEX_CHORD_HOLDING_TIME
  #endif
  #ifndef INDEX_STREAK_DECAY
  #define INDEX_STREAK_DECAY HOMEY_STREAK_DECAY
  #endif
  #ifndef INDEX_CHORD_STREAK_DECAY
  #define INDEX_CHORD_STREAK_DECAY CHORD_STREAK_DECAY
  #endif
  #ifndef LEFT_INDEX_CHORD_STREAK_DECAY
  #define LEFT_INDEX_CHORD_STREAK_DECAY INDEX_CHORD_STREAK_DECAY
  #endif
  #ifndef RIGHT_INDEX_CHORD_STREAK_DECAY
  #define RIGHT_INDEX_CHORD_STREAK_DECAY INDEX_CHORD_STREAK_DECAY
  #endif
  #ifndef LEFT_PINKY_HOLDING_TYPE
  #define LEFT_PINKY_HOLDING_TYPE PINKY_HOLDING_TYPE
  #endif
  #ifndef LEFT_PINKY_HOLDING_TIME
  #define LEFT_PINKY_HOLDING_TIME PINKY_HOLDING_TIME
  #endif
  #ifndef LEFT_PINKY_STREAK_DECAY
  #define LEFT_PINKY_STREAK_DECAY PINKY_STREAK_DECAY
  #endif
  left_pinky: homey_left_pinky {
    compatible = "zmk,behavior-hold-tap";
    flavor = LEFT_PINKY_HOLDING_TYPE;
    hold-trigger-key-positions = <RIGHT_HAND_KEYS THUMB_KEYS>;
    hold-trigger-on-release; // wait for other home row mods
    tapping-term-ms = <LEFT_PINKY_HOLDING_TIME>;
    require-prior-idle-ms = <LEFT_PINKY_STREAK_DECAY>;
    #binding-cells = <2>;
    bindings = <&kp>, <&kp>;
    #ifdef SHIFT_FORGIVENESS
    #if LEFT_PINKY_MOD == LSFT || LEFT_PINKY_MOD == RSFT
    hold-while-undecided; // requires 24.08-beta1 or newer firmware
    retro-tap; // tap on standalone hold
    #endif
    #endif
  };
  left_pinky_bilateral: homey_left_pinky_bilateral {
    compatible = "zmk,behavior-hold-tap";
    flavor = LEFT_PINKY_HOLDING_TYPE;
    hold-trigger-key-positions = <RIGHT_HAND_KEYS THUMB_KEYS>;
    hold-trigger-on-release; // wait for other home row mods
    tapping-term-ms = <LEFT_PINKY_HOLDING_TIME>;
    require-prior-idle-ms = <LEFT_PINKY_STREAK_DECAY>;
    #binding-cells = <2>;
    bindings = <&left_pinky_hold>, <&kp>;
    #ifdef SHIFT_FORGIVENESS
    #if LEFT_PINKY_MOD == LSFT || LEFT_PINKY_MOD == RSFT
    hold-while-undecided; // requires 24.08-beta1 or newer firmware
    retro-tap; // tap on standalone hold
    #endif
    #endif
  };
  left_pinky_hold: homey_left_pinky_hold {
    compatible = "zmk,behavior-macro-one-param";
    wait-ms = <0>;
    tap-ms = <0>;
    #binding-cells = <1>;
    bindings
      = <&macro_param_1to1>
      , <&macro_press &kp MACRO_PLACEHOLDER>
      #ifdef LAYER_LeftPinky
      , <&macro_press &mo LAYER_LeftPinky>
      #endif
      , <&macro_pause_for_release>
      , <&macro_param_1to1>
      , <&macro_release &kp MACRO_PLACEHOLDER>
      #ifdef LAYER_LeftPinky
      , <&macro_release &mo LAYER_LeftPinky>
      #endif
      ;
  };
  left_pinky_tap: homey_left_pinky_tap {
    compatible = "zmk,behavior-macro-one-param";
    wait-ms = <0>;
    tap-ms = <0>;
    #binding-cells = <1>;
    bindings
      = <&macro_release
          &kp LSFT &kp RSFT
          &kp LALT &kp RALT
          &kp LCTL &kp RCTL
          &kp LGUI &kp RGUI>
      , <&macro_tap &kp LEFT_PINKY_KEY>
      , <&macro_param_1to1>
      , <&macro_tap &kp MACRO_PLACEHOLDER>
      ;
  };
  #define LeftPinky(key, layer_index) LeftPinky_unroll(layer_index) (key)
  #define LeftPinky_unroll(layer_index) LeftPinky_concat(LeftPinky_layer, layer_index)
  #define LeftPinky_concat(prefix, layer_index) prefix ## layer_index
  #ifdef ENFORCE_BILATERAL
  #define left_pinky_layer0_variant left_pinky_bilateral
  #else
  #define left_pinky_layer0_variant left_pinky
  #endif
  #define LeftPinky_layer0(key) left_pinky_layer0_variant LEFT_PINKY_MOD key
  #define LeftPinky_layer1(key) left_pinky LEFT_PINKY_MOD key
  #define LeftPinky_layer2(key) left_pinky LEFT_PINKY_MOD key
  #define LeftPinky_layer3(key) left_pinky LEFT_PINKY_MOD key
  #define LeftPinky_layer4(key) left_pinky LEFT_PINKY_MOD key
  #define LeftPinky_layer5(key) left_pinky LEFT_PINKY_MOD key
  #define LeftPinky_layer6(key) left_pinky LEFT_PINKY_MOD key
  #define LeftPinky_layer7(key) left_pinky LEFT_PINKY_MOD key
  #define LeftPinky_layer8(key) left_pinky LEFT_PINKY_MOD key
  #define LeftPinky_layer9(key) left_pinky LEFT_PINKY_MOD key
  #define LeftPinky_layer10(key) left_pinky LEFT_PINKY_MOD key
  #ifndef RIGHT_PINKY_HOLDING_TYPE
  #define RIGHT_PINKY_HOLDING_TYPE PINKY_HOLDING_TYPE
  #endif
  #ifndef RIGHT_PINKY_HOLDING_TIME
  #define RIGHT_PINKY_HOLDING_TIME PINKY_HOLDING_TIME
  #endif
  #ifndef RIGHT_PINKY_STREAK_DECAY
  #define RIGHT_PINKY_STREAK_DECAY PINKY_STREAK_DECAY
  #endif
  right_pinky: homey_right_pinky {
    compatible = "zmk,behavior-hold-tap";
    flavor = RIGHT_PINKY_HOLDING_TYPE;
    hold-trigger-key-positions = <LEFT_HAND_KEYS THUMB_KEYS>;
    hold-trigger-on-release; // wait for other home row mods
    tapping-term-ms = <RIGHT_PINKY_HOLDING_TIME>;
    require-prior-idle-ms = <RIGHT_PINKY_STREAK_DECAY>;
    #binding-cells = <2>;
    bindings = <&kp>, <&kp>;
    #ifdef SHIFT_FORGIVENESS
    #if RIGHT_PINKY_MOD == LSFT || RIGHT_PINKY_MOD == RSFT
    hold-while-undecided; // requires 24.08-beta1 or newer firmware
    retro-tap; // tap on standalone hold
    #endif
    #endif
  };
  right_pinky_bilateral: homey_right_pinky_bilateral {
    compatible = "zmk,behavior-hold-tap";
    flavor = RIGHT_PINKY_HOLDING_TYPE;
    hold-trigger-key-positions = <LEFT_HAND_KEYS THUMB_KEYS>;
    hold-trigger-on-release; // wait for other home row mods
    tapping-term-ms = <RIGHT_PINKY_HOLDING_TIME>;
    require-prior-idle-ms = <RIGHT_PINKY_STREAK_DECAY>;
    #binding-cells = <2>;
    bindings = <&right_pinky_hold>, <&kp>;
    #ifdef SHIFT_FORGIVENESS
    #if RIGHT_PINKY_MOD == LSFT || RIGHT_PINKY_MOD == RSFT
    hold-while-undecided; // requires 24.08-beta1 or newer firmware
    retro-tap; // tap on standalone hold
    #endif
    #endif
  };
  right_pinky_hold: homey_right_pinky_hold {
    compatible = "zmk,behavior-macro-one-param";
    wait-ms = <0>;
    tap-ms = <0>;
    #binding-cells = <1>;
    bindings
      = <&macro_param_1to1>
      , <&macro_press &kp MACRO_PLACEHOLDER>
      #ifdef LAYER_RightPinky
      , <&macro_press &mo LAYER_RightPinky>
      #endif
      , <&macro_pause_for_release>
      , <&macro_param_1to1>
      , <&macro_release &kp MACRO_PLACEHOLDER>
      #ifdef LAYER_RightPinky
      , <&macro_release &mo LAYER_RightPinky>
      #endif
      ;
  };
  right_pinky_tap: homey_right_pinky_tap {
    compatible = "zmk,behavior-macro-one-param";
    wait-ms = <0>;
    tap-ms = <0>;
    #binding-cells = <1>;
    bindings
      = <&macro_release
          &kp LSFT &kp RSFT
          &kp LALT &kp RALT
          &kp LCTL &kp RCTL
          &kp LGUI &kp RGUI>
      , <&macro_tap &kp RIGHT_PINKY_KEY>
      , <&macro_param_1to1>
      , <&macro_tap &kp MACRO_PLACEHOLDER>
      ;
  };
  #define RightPinky(key, layer_index) RightPinky_unroll(layer_index) (key)
  #define RightPinky_unroll(layer_index) RightPinky_concat(RightPinky_layer, layer_index)
  #define RightPinky_concat(prefix, layer_index) prefix ## layer_index
  #ifdef ENFORCE_BILATERAL
  #define right_pinky_layer0_variant right_pinky_bilateral
  #else
  #define right_pinky_layer0_variant right_pinky
  #endif
  #define RightPinky_layer0(key) right_pinky_layer0_variant RIGHT_PINKY_MOD key
  #define RightPinky_layer1(key) right_pinky RIGHT_PINKY_MOD key
  #define RightPinky_layer2(key) right_pinky RIGHT_PINKY_MOD key
  #define RightPinky_layer3(key) right_pinky RIGHT_PINKY_MOD key
  #define RightPinky_layer4(key) right_pinky RIGHT_PINKY_MOD key
  #define RightPinky_layer5(key) right_pinky RIGHT_PINKY_MOD key
  #define RightPinky_layer6(key) right_pinky RIGHT_PINKY_MOD key
  #define RightPinky_layer7(key) right_pinky RIGHT_PINKY_MOD key
  #define RightPinky_layer8(key) right_pinky RIGHT_PINKY_MOD key
  #define RightPinky_layer9(key) right_pinky RIGHT_PINKY_MOD key
  #define RightPinky_layer10(key) right_pinky RIGHT_PINKY_MOD key
  #ifndef LEFT_RINGY_HOLDING_TYPE
  #define LEFT_RINGY_HOLDING_TYPE RINGY_HOLDING_TYPE
  #endif
  #ifndef LEFT_RINGY_HOLDING_TIME
  #define LEFT_RINGY_HOLDING_TIME RINGY_HOLDING_TIME
  #endif
  #ifndef LEFT_RINGY_STREAK_DECAY
  #define LEFT_RINGY_STREAK_DECAY RINGY_STREAK_DECAY
  #endif
  left_ringy: homey_left_ringy {
    compatible = "zmk,behavior-hold-tap";
    flavor = LEFT_RINGY_HOLDING_TYPE;
    hold-trigger-key-positions = <RIGHT_HAND_KEYS THUMB_KEYS>;
    hold-trigger-on-release; // wait for other home row mods
    tapping-term-ms = <LEFT_RINGY_HOLDING_TIME>;
    require-prior-idle-ms = <LEFT_RINGY_STREAK_DECAY>;
    #binding-cells = <2>;
    bindings = <&kp>, <&kp>;
    #ifdef SHIFT_FORGIVENESS
    #if LEFT_RINGY_MOD == LSFT || LEFT_RINGY_MOD == RSFT
    hold-while-undecided; // requires 24.08-beta1 or newer firmware
    retro-tap; // tap on standalone hold
    #endif
    #endif
  };
  left_ringy_bilateral: homey_left_ringy_bilateral {
    compatible = "zmk,behavior-hold-tap";
    flavor = LEFT_RINGY_HOLDING_TYPE;
    hold-trigger-key-positions = <RIGHT_HAND_KEYS THUMB_KEYS>;
    hold-trigger-on-release; // wait for other home row mods
    tapping-term-ms = <LEFT_RINGY_HOLDING_TIME>;
    require-prior-idle-ms = <LEFT_RINGY_STREAK_DECAY>;
    #binding-cells = <2>;
    bindings = <&left_ringy_hold>, <&kp>;
    #ifdef SHIFT_FORGIVENESS
    #if LEFT_RINGY_MOD == LSFT || LEFT_RINGY_MOD == RSFT
    hold-while-undecided; // requires 24.08-beta1 or newer firmware
    retro-tap; // tap on standalone hold
    #endif
    #endif
  };
  left_ringy_hold: homey_left_ringy_hold {
    compatible = "zmk,behavior-macro-one-param";
    wait-ms = <0>;
    tap-ms = <0>;
    #binding-cells = <1>;
    bindings
      = <&macro_param_1to1>
      , <&macro_press &kp MACRO_PLACEHOLDER>
      #ifdef LAYER_LeftRingy
      , <&macro_press &mo LAYER_LeftRingy>
      #endif
      , <&macro_pause_for_release>
      , <&macro_param_1to1>
      , <&macro_release &kp MACRO_PLACEHOLDER>
      #ifdef LAYER_LeftRingy
      , <&macro_release &mo LAYER_LeftRingy>
      #endif
      ;
  };
  left_ringy_tap: homey_left_ringy_tap {
    compatible = "zmk,behavior-macro-one-param";
    wait-ms = <0>;
    tap-ms = <0>;
    #binding-cells = <1>;
    bindings
      = <&macro_release
          &kp LSFT &kp RSFT
          &kp LALT &kp RALT
          &kp LCTL &kp RCTL
          &kp LGUI &kp RGUI>
      , <&macro_tap &kp LEFT_RINGY_KEY>
      , <&macro_param_1to1>
      , <&macro_tap &kp MACRO_PLACEHOLDER>
      ;
  };
  #define LeftRingy(key, layer_index) LeftRingy_unroll(layer_index) (key)
  #define LeftRingy_unroll(layer_index) LeftRingy_concat(LeftRingy_layer, layer_index)
  #define LeftRingy_concat(prefix, layer_index) prefix ## layer_index
  #ifdef ENFORCE_BILATERAL
  #define left_ringy_layer0_variant left_ringy_bilateral
  #else
  #define left_ringy_layer0_variant left_ringy
  #endif
  #define LeftRingy_layer0(key) left_ringy_layer0_variant LEFT_RINGY_MOD key
  #define LeftRingy_layer1(key) left_ringy LEFT_RINGY_MOD key
  #define LeftRingy_layer2(key) left_ringy LEFT_RINGY_MOD key
  #define LeftRingy_layer3(key) left_ringy LEFT_RINGY_MOD key
  #define LeftRingy_layer4(key) left_ringy LEFT_RINGY_MOD key
  #define LeftRingy_layer5(key) left_ringy LEFT_RINGY_MOD key
  #define LeftRingy_layer6(key) left_ringy LEFT_RINGY_MOD key
  #define LeftRingy_layer7(key) left_ringy LEFT_RINGY_MOD key
  #define LeftRingy_layer8(key) left_ringy LEFT_RINGY_MOD key
  #define LeftRingy_layer9(key) left_ringy LEFT_RINGY_MOD key
  #define LeftRingy_layer10(key) left_ringy LEFT_RINGY_MOD key
  #ifndef RIGHT_RINGY_HOLDING_TYPE
  #define RIGHT_RINGY_HOLDING_TYPE RINGY_HOLDING_TYPE
  #endif
  #ifndef RIGHT_RINGY_HOLDING_TIME
  #define RIGHT_RINGY_HOLDING_TIME RINGY_HOLDING_TIME
  #endif
  #ifndef RIGHT_RINGY_STREAK_DECAY
  #define RIGHT_RINGY_STREAK_DECAY RINGY_STREAK_DECAY
  #endif
  right_ringy: homey_right_ringy {
    compatible = "zmk,behavior-hold-tap";
    flavor = RIGHT_RINGY_HOLDING_TYPE;
    hold-trigger-key-positions = <LEFT_HAND_KEYS THUMB_KEYS>;
    hold-trigger-on-release; // wait for other home row mods
    tapping-term-ms = <RIGHT_RINGY_HOLDING_TIME>;
    require-prior-idle-ms = <RIGHT_RINGY_STREAK_DECAY>;
    #binding-cells = <2>;
    bindings = <&kp>, <&kp>;
    #ifdef SHIFT_FORGIVENESS
    #if RIGHT_RINGY_MOD == LSFT || RIGHT_RINGY_MOD == RSFT
    hold-while-undecided; // requires 24.08-beta1 or newer firmware
    retro-tap; // tap on standalone hold
    #endif
    #endif
  };
  right_ringy_bilateral: homey_right_ringy_bilateral {
    compatible = "zmk,behavior-hold-tap";
    flavor = RIGHT_RINGY_HOLDING_TYPE;
    hold-trigger-key-positions = <LEFT_HAND_KEYS THUMB_KEYS>;
    hold-trigger-on-release; // wait for other home row mods
    tapping-term-ms = <RIGHT_RINGY_HOLDING_TIME>;
    require-prior-idle-ms = <RIGHT_RINGY_STREAK_DECAY>;
    #binding-cells = <2>;
    bindings = <&right_ringy_hold>, <&kp>;
    #ifdef SHIFT_FORGIVENESS
    #if RIGHT_RINGY_MOD == LSFT || RIGHT_RINGY_MOD == RSFT
    hold-while-undecided; // requires 24.08-beta1 or newer firmware
    retro-tap; // tap on standalone hold
    #endif
    #endif
  };
  right_ringy_hold: homey_right_ringy_hold {
    compatible = "zmk,behavior-macro-one-param";
    wait-ms = <0>;
    tap-ms = <0>;
    #binding-cells = <1>;
    bindings
      = <&macro_param_1to1>
      , <&macro_press &kp MACRO_PLACEHOLDER>
      #ifdef LAYER_RightRingy
      , <&macro_press &mo LAYER_RightRingy>
      #endif
      , <&macro_pause_for_release>
      , <&macro_param_1to1>
      , <&macro_release &kp MACRO_PLACEHOLDER>
      #ifdef LAYER_RightRingy
      , <&macro_release &mo LAYER_RightRingy>
      #endif
      ;
  };
  right_ringy_tap: homey_right_ringy_tap {
    compatible = "zmk,behavior-macro-one-param";
    wait-ms = <0>;
    tap-ms = <0>;
    #binding-cells = <1>;
    bindings
      = <&macro_release
          &kp LSFT &kp RSFT
          &kp LALT &kp RALT
          &kp LCTL &kp RCTL
          &kp LGUI &kp RGUI>
      , <&macro_tap &kp RIGHT_RINGY_KEY>
      , <&macro_param_1to1>
      , <&macro_tap &kp MACRO_PLACEHOLDER>
      ;
  };
  #define RightRingy(key, layer_index) RightRingy_unroll(layer_index) (key)
  #define RightRingy_unroll(layer_index) RightRingy_concat(RightRingy_layer, layer_index)
  #define RightRingy_concat(prefix, layer_index) prefix ## layer_index
  #ifdef ENFORCE_BILATERAL
  #define right_ringy_layer0_variant right_ringy_bilateral
  #else
  #define right_ringy_layer0_variant right_ringy
  #endif
  #define RightRingy_layer0(key) right_ringy_layer0_variant RIGHT_RINGY_MOD key
  #define RightRingy_layer1(key) right_ringy RIGHT_RINGY_MOD key
  #define RightRingy_layer2(key) right_ringy RIGHT_RINGY_MOD key
  #define RightRingy_layer3(key) right_ringy RIGHT_RINGY_MOD key
  #define RightRingy_layer4(key) right_ringy RIGHT_RINGY_MOD key
  #define RightRingy_layer5(key) right_ringy RIGHT_RINGY_MOD key
  #define RightRingy_layer6(key) right_ringy RIGHT_RINGY_MOD key
  #define RightRingy_layer7(key) right_ringy RIGHT_RINGY_MOD key
  #define RightRingy_layer8(key) right_ringy RIGHT_RINGY_MOD key
  #define RightRingy_layer9(key) right_ringy RIGHT_RINGY_MOD key
  #define RightRingy_layer10(key) right_ringy RIGHT_RINGY_MOD key
  #ifndef LEFT_MIDDY_HOLDING_TYPE
  #define LEFT_MIDDY_HOLDING_TYPE MIDDY_HOLDING_TYPE
  #endif
  #ifndef LEFT_MIDDY_HOLDING_TIME
  #define LEFT_MIDDY_HOLDING_TIME MIDDY_HOLDING_TIME
  #endif
  #ifndef LEFT_MIDDY_STREAK_DECAY
  #define LEFT_MIDDY_STREAK_DECAY MIDDY_STREAK_DECAY
  #endif
  left_middy: homey_left_middy {
    compatible = "zmk,behavior-hold-tap";
    flavor = LEFT_MIDDY_HOLDING_TYPE;
    hold-trigger-key-positions = <RIGHT_HAND_KEYS THUMB_KEYS>;
    hold-trigger-on-release; // wait for other home row mods
    tapping-term-ms = <LEFT_MIDDY_HOLDING_TIME>;
    require-prior-idle-ms = <LEFT_MIDDY_STREAK_DECAY>;
    #binding-cells = <2>;
    bindings = <&kp>, <&kp>;
    #ifdef SHIFT_FORGIVENESS
    #if LEFT_MIDDY_MOD == LSFT || LEFT_MIDDY_MOD == RSFT
    hold-while-undecided; // requires 24.08-beta1 or newer firmware
    retro-tap; // tap on standalone hold
    #endif
    #endif
  };
  left_middy_bilateral: homey_left_middy_bilateral {
    compatible = "zmk,behavior-hold-tap";
    flavor = LEFT_MIDDY_HOLDING_TYPE;
    hold-trigger-key-positions = <RIGHT_HAND_KEYS THUMB_KEYS>;
    hold-trigger-on-release; // wait for other home row mods
    tapping-term-ms = <LEFT_MIDDY_HOLDING_TIME>;
    require-prior-idle-ms = <LEFT_MIDDY_STREAK_DECAY>;
    #binding-cells = <2>;
    bindings = <&left_middy_hold>, <&kp>;
    #ifdef SHIFT_FORGIVENESS
    #if LEFT_MIDDY_MOD == LSFT || LEFT_MIDDY_MOD == RSFT
    hold-while-undecided; // requires 24.08-beta1 or newer firmware
    retro-tap; // tap on standalone hold
    #endif
    #endif
  };
  left_middy_hold: homey_left_middy_hold {
    compatible = "zmk,behavior-macro-one-param";
    wait-ms = <0>;
    tap-ms = <0>;
    #binding-cells = <1>;
    bindings
      = <&macro_param_1to1>
      , <&macro_press &kp MACRO_PLACEHOLDER>
      #ifdef LAYER_LeftMiddy
      , <&macro_press &mo LAYER_LeftMiddy>
      #endif
      , <&macro_pause_for_release>
      , <&macro_param_1to1>
      , <&macro_release &kp MACRO_PLACEHOLDER>
      #ifdef LAYER_LeftMiddy
      , <&macro_release &mo LAYER_LeftMiddy>
      #endif
      ;
  };
  left_middy_tap: homey_left_middy_tap {
    compatible = "zmk,behavior-macro-one-param";
    wait-ms = <0>;
    tap-ms = <0>;
    #binding-cells = <1>;
    bindings
      = <&macro_release
          &kp LSFT &kp RSFT
          &kp LALT &kp RALT
          &kp LCTL &kp RCTL
          &kp LGUI &kp RGUI>
      , <&macro_tap &kp LEFT_MIDDY_KEY>
      , <&macro_param_1to1>
      , <&macro_tap &kp MACRO_PLACEHOLDER>
      ;
  };
  #define LeftMiddy(key, layer_index) LeftMiddy_unroll(layer_index) (key)
  #define LeftMiddy_unroll(layer_index) LeftMiddy_concat(LeftMiddy_layer, layer_index)
  #define LeftMiddy_concat(prefix, layer_index) prefix ## layer_index
  #ifdef ENFORCE_BILATERAL
  #define left_middy_layer0_variant left_middy_bilateral
  #else
  #define left_middy_layer0_variant left_middy
  #endif
  #define LeftMiddy_layer0(key) left_middy_layer0_variant LEFT_MIDDY_MOD key
  #define LeftMiddy_layer1(key) left_middy LEFT_MIDDY_MOD key
  #define LeftMiddy_layer2(key) left_middy LEFT_MIDDY_MOD key
  #define LeftMiddy_layer3(key) left_middy LEFT_MIDDY_MOD key
  #define LeftMiddy_layer4(key) left_middy LEFT_MIDDY_MOD key
  #define LeftMiddy_layer5(key) left_middy LEFT_MIDDY_MOD key
  #define LeftMiddy_layer6(key) left_middy LEFT_MIDDY_MOD key
  #define LeftMiddy_layer7(key) left_middy LEFT_MIDDY_MOD key
  #define LeftMiddy_layer8(key) left_middy LEFT_MIDDY_MOD key
  #define LeftMiddy_layer9(key) left_middy LEFT_MIDDY_MOD key
  #define LeftMiddy_layer10(key) left_middy LEFT_MIDDY_MOD key
  #ifndef RIGHT_MIDDY_HOLDING_TYPE
  #define RIGHT_MIDDY_HOLDING_TYPE MIDDY_HOLDING_TYPE
  #endif
  #ifndef RIGHT_MIDDY_HOLDING_TIME
  #define RIGHT_MIDDY_HOLDING_TIME MIDDY_HOLDING_TIME
  #endif
  #ifndef RIGHT_MIDDY_STREAK_DECAY
  #define RIGHT_MIDDY_STREAK_DECAY MIDDY_STREAK_DECAY
  #endif
  right_middy: homey_right_middy {
    compatible = "zmk,behavior-hold-tap";
    flavor = RIGHT_MIDDY_HOLDING_TYPE;
    hold-trigger-key-positions = <LEFT_HAND_KEYS THUMB_KEYS>;
    hold-trigger-on-release; // wait for other home row mods
    tapping-term-ms = <RIGHT_MIDDY_HOLDING_TIME>;
    require-prior-idle-ms = <RIGHT_MIDDY_STREAK_DECAY>;
    #binding-cells = <2>;
    bindings = <&kp>, <&kp>;
    #ifdef SHIFT_FORGIVENESS
    #if RIGHT_MIDDY_MOD == LSFT || RIGHT_MIDDY_MOD == RSFT
    hold-while-undecided; // requires 24.08-beta1 or newer firmware
    retro-tap; // tap on standalone hold
    #endif
    #endif
  };
  right_middy_bilateral: homey_right_middy_bilateral {
    compatible = "zmk,behavior-hold-tap";
    flavor = RIGHT_MIDDY_HOLDING_TYPE;
    hold-trigger-key-positions = <LEFT_HAND_KEYS THUMB_KEYS>;
    hold-trigger-on-release; // wait for other home row mods
    tapping-term-ms = <RIGHT_MIDDY_HOLDING_TIME>;
    require-prior-idle-ms = <RIGHT_MIDDY_STREAK_DECAY>;
    #binding-cells = <2>;
    bindings = <&right_middy_hold>, <&kp>;
    #ifdef SHIFT_FORGIVENESS
    #if RIGHT_MIDDY_MOD == LSFT || RIGHT_MIDDY_MOD == RSFT
    hold-while-undecided; // requires 24.08-beta1 or newer firmware
    retro-tap; // tap on standalone hold
    #endif
    #endif
  };
  right_middy_hold: homey_right_middy_hold {
    compatible = "zmk,behavior-macro-one-param";
    wait-ms = <0>;
    tap-ms = <0>;
    #binding-cells = <1>;
    bindings
      = <&macro_param_1to1>
      , <&macro_press &kp MACRO_PLACEHOLDER>
      #ifdef LAYER_RightMiddy
      , <&macro_press &mo LAYER_RightMiddy>
      #endif
      , <&macro_pause_for_release>
      , <&macro_param_1to1>
      , <&macro_release &kp MACRO_PLACEHOLDER>
      #ifdef LAYER_RightMiddy
      , <&macro_release &mo LAYER_RightMiddy>
      #endif
      ;
  };
  right_middy_tap: homey_right_middy_tap {
    compatible = "zmk,behavior-macro-one-param";
    wait-ms = <0>;
    tap-ms = <0>;
    #binding-cells = <1>;
    bindings
      = <&macro_release
          &kp LSFT &kp RSFT
          &kp LALT &kp RALT
          &kp LCTL &kp RCTL
          &kp LGUI &kp RGUI>
      , <&macro_tap &kp RIGHT_MIDDY_KEY>
      , <&macro_param_1to1>
      , <&macro_tap &kp MACRO_PLACEHOLDER>
      ;
  };
  #define RightMiddy(key, layer_index) RightMiddy_unroll(layer_index) (key)
  #define RightMiddy_unroll(layer_index) RightMiddy_concat(RightMiddy_layer, layer_index)
  #define RightMiddy_concat(prefix, layer_index) prefix ## layer_index
  #ifdef ENFORCE_BILATERAL
  #define right_middy_layer0_variant right_middy_bilateral
  #else
  #define right_middy_layer0_variant right_middy
  #endif
  #define RightMiddy_layer0(key) right_middy_layer0_variant RIGHT_MIDDY_MOD key
  #define RightMiddy_layer1(key) right_middy RIGHT_MIDDY_MOD key
  #define RightMiddy_layer2(key) right_middy RIGHT_MIDDY_MOD key
  #define RightMiddy_layer3(key) right_middy RIGHT_MIDDY_MOD key
  #define RightMiddy_layer4(key) right_middy RIGHT_MIDDY_MOD key
  #define RightMiddy_layer5(key) right_middy RIGHT_MIDDY_MOD key
  #define RightMiddy_layer6(key) right_middy RIGHT_MIDDY_MOD key
  #define RightMiddy_layer7(key) right_middy RIGHT_MIDDY_MOD key
  #define RightMiddy_layer8(key) right_middy RIGHT_MIDDY_MOD key
  #define RightMiddy_layer9(key) right_middy RIGHT_MIDDY_MOD key
  #define RightMiddy_layer10(key) right_middy RIGHT_MIDDY_MOD key
  #ifndef LEFT_INDEX_HOLDING_TYPE
  #define LEFT_INDEX_HOLDING_TYPE INDEX_HOLDING_TYPE
  #endif
  #ifndef LEFT_INDEX_HOLDING_TIME
  #define LEFT_INDEX_HOLDING_TIME INDEX_HOLDING_TIME
  #endif
  #ifndef LEFT_INDEX_STREAK_DECAY
  #define LEFT_INDEX_STREAK_DECAY INDEX_STREAK_DECAY
  #endif
  left_index: homey_left_index {
    compatible = "zmk,behavior-hold-tap";
    flavor = LEFT_INDEX_HOLDING_TYPE;
    hold-trigger-key-positions = <RIGHT_HAND_KEYS THUMB_KEYS>;
    hold-trigger-on-release; // wait for other home row mods
    tapping-term-ms = <LEFT_INDEX_HOLDING_TIME>;
    require-prior-idle-ms = <LEFT_INDEX_STREAK_DECAY>;
    #binding-cells = <2>;
    bindings = <&kp>, <&kp>;
    #ifdef SHIFT_FORGIVENESS
    #if LEFT_INDEX_MOD == LSFT || LEFT_INDEX_MOD == RSFT
    hold-while-undecided; // requires 24.08-beta1 or newer firmware
    retro-tap; // tap on standalone hold
    #endif
    #endif
  };
  left_index_bilateral: homey_left_index_bilateral {
    compatible = "zmk,behavior-hold-tap";
    flavor = LEFT_INDEX_HOLDING_TYPE;
    hold-trigger-key-positions = <RIGHT_HAND_KEYS THUMB_KEYS>;
    hold-trigger-on-release; // wait for other home row mods
    tapping-term-ms = <LEFT_INDEX_HOLDING_TIME>;
    require-prior-idle-ms = <LEFT_INDEX_STREAK_DECAY>;
    #binding-cells = <2>;
    bindings = <&left_index_hold>, <&kp>;
    #ifdef SHIFT_FORGIVENESS
    #if LEFT_INDEX_MOD == LSFT || LEFT_INDEX_MOD == RSFT
    hold-while-undecided; // requires 24.08-beta1 or newer firmware
    retro-tap; // tap on standalone hold
    #endif
    #endif
  };
  left_index_hold: homey_left_index_hold {
    compatible = "zmk,behavior-macro-one-param";
    wait-ms = <0>;
    tap-ms = <0>;
    #binding-cells = <1>;
    bindings
      = <&macro_param_1to1>
      , <&macro_press &kp MACRO_PLACEHOLDER>
      #ifdef LAYER_LeftIndex
      , <&macro_press &mo LAYER_LeftIndex>
      #endif
      , <&macro_pause_for_release>
      , <&macro_param_1to1>
      , <&macro_release &kp MACRO_PLACEHOLDER>
      #ifdef LAYER_LeftIndex
      , <&macro_release &mo LAYER_LeftIndex>
      #endif
      ;
  };
  left_index_tap: homey_left_index_tap {
    compatible = "zmk,behavior-macro-one-param";
    wait-ms = <0>;
    tap-ms = <0>;
    #binding-cells = <1>;
    bindings
      = <&macro_release
          &kp LSFT &kp RSFT
          &kp LALT &kp RALT
          &kp LCTL &kp RCTL
          &kp LGUI &kp RGUI>
      , <&macro_tap &kp LEFT_INDEX_KEY>
      , <&macro_param_1to1>
      , <&macro_tap &kp MACRO_PLACEHOLDER>
      ;
  };
  #define LeftIndex(key, layer_index) LeftIndex_unroll(layer_index) (key)
  #define LeftIndex_unroll(layer_index) LeftIndex_concat(LeftIndex_layer, layer_index)
  #define LeftIndex_concat(prefix, layer_index) prefix ## layer_index
  #ifdef ENFORCE_BILATERAL
  #define left_index_layer0_variant left_index_bilateral
  #else
  #define left_index_layer0_variant left_index
  #endif
  #define LeftIndex_layer0(key) left_index_layer0_variant LEFT_INDEX_MOD key
  #define LeftIndex_layer1(key) left_index LEFT_INDEX_MOD key
  #define LeftIndex_layer2(key) left_index LEFT_INDEX_MOD key
  #define LeftIndex_layer3(key) left_index LEFT_INDEX_MOD key
  #define LeftIndex_layer4(key) left_index LEFT_INDEX_MOD key
  #define LeftIndex_layer5(key) left_index LEFT_INDEX_MOD key
  #define LeftIndex_layer6(key) left_index LEFT_INDEX_MOD key
  #define LeftIndex_layer7(key) left_index LEFT_INDEX_MOD key
  #define LeftIndex_layer8(key) left_index LEFT_INDEX_MOD key
  #define LeftIndex_layer9(key) left_index LEFT_INDEX_MOD key
  #define LeftIndex_layer10(key) left_index LEFT_INDEX_MOD key
  #ifndef RIGHT_INDEX_HOLDING_TYPE
  #define RIGHT_INDEX_HOLDING_TYPE INDEX_HOLDING_TYPE
  #endif
  #ifndef RIGHT_INDEX_HOLDING_TIME
  #define RIGHT_INDEX_HOLDING_TIME INDEX_HOLDING_TIME
  #endif
  #ifndef RIGHT_INDEX_STREAK_DECAY
  #define RIGHT_INDEX_STREAK_DECAY INDEX_STREAK_DECAY
  #endif
  right_index: homey_right_index {
    compatible = "zmk,behavior-hold-tap";
    flavor = RIGHT_INDEX_HOLDING_TYPE;
    hold-trigger-key-positions = <LEFT_HAND_KEYS THUMB_KEYS>;
    hold-trigger-on-release; // wait for other home row mods
    tapping-term-ms = <RIGHT_INDEX_HOLDING_TIME>;
    require-prior-idle-ms = <RIGHT_INDEX_STREAK_DECAY>;
    #binding-cells = <2>;
    bindings = <&kp>, <&kp>;
    #ifdef SHIFT_FORGIVENESS
    #if RIGHT_INDEX_MOD == LSFT || RIGHT_INDEX_MOD == RSFT
    hold-while-undecided; // requires 24.08-beta1 or newer firmware
    retro-tap; // tap on standalone hold
    #endif
    #endif
  };
  right_index_bilateral: homey_right_index_bilateral {
    compatible = "zmk,behavior-hold-tap";
    flavor = RIGHT_INDEX_HOLDING_TYPE;
    hold-trigger-key-positions = <LEFT_HAND_KEYS THUMB_KEYS>;
    hold-trigger-on-release; // wait for other home row mods
    tapping-term-ms = <RIGHT_INDEX_HOLDING_TIME>;
    require-prior-idle-ms = <RIGHT_INDEX_STREAK_DECAY>;
    #binding-cells = <2>;
    bindings = <&right_index_hold>, <&kp>;
    #ifdef SHIFT_FORGIVENESS
    #if RIGHT_INDEX_MOD == LSFT || RIGHT_INDEX_MOD == RSFT
    hold-while-undecided; // requires 24.08-beta1 or newer firmware
    retro-tap; // tap on standalone hold
    #endif
    #endif
  };
  right_index_hold: homey_right_index_hold {
    compatible = "zmk,behavior-macro-one-param";
    wait-ms = <0>;
    tap-ms = <0>;
    #binding-cells = <1>;
    bindings
      = <&macro_param_1to1>
      , <&macro_press &kp MACRO_PLACEHOLDER>
      #ifdef LAYER_RightIndex
      , <&macro_press &mo LAYER_RightIndex>
      #endif
      , <&macro_pause_for_release>
      , <&macro_param_1to1>
      , <&macro_release &kp MACRO_PLACEHOLDER>
      #ifdef LAYER_RightIndex
      , <&macro_release &mo LAYER_RightIndex>
      #endif
      ;
  };
  right_index_tap: homey_right_index_tap {
    compatible = "zmk,behavior-macro-one-param";
    wait-ms = <0>;
    tap-ms = <0>;
    #binding-cells = <1>;
    bindings
      = <&macro_release
          &kp LSFT &kp RSFT
          &kp LALT &kp RALT
          &kp LCTL &kp RCTL
          &kp LGUI &kp RGUI>
      , <&macro_tap &kp RIGHT_INDEX_KEY>
      , <&macro_param_1to1>
      , <&macro_tap &kp MACRO_PLACEHOLDER>
      ;
  };
  #define RightIndex(key, layer_index) RightIndex_unroll(layer_index) (key)
  #define RightIndex_unroll(layer_index) RightIndex_concat(RightIndex_layer, layer_index)
  #define RightIndex_concat(prefix, layer_index) prefix ## layer_index
  #ifdef ENFORCE_BILATERAL
  #define right_index_layer0_variant right_index_bilateral
  #else
  #define right_index_layer0_variant right_index
  #endif
  #define RightIndex_layer0(key) right_index_layer0_variant RIGHT_INDEX_MOD key
  #define RightIndex_layer1(key) right_index RIGHT_INDEX_MOD key
  #define RightIndex_layer2(key) right_index RIGHT_INDEX_MOD key
  #define RightIndex_layer3(key) right_index RIGHT_INDEX_MOD key
  #define RightIndex_layer4(key) right_index RIGHT_INDEX_MOD key
  #define RightIndex_layer5(key) right_index RIGHT_INDEX_MOD key
  #define RightIndex_layer6(key) right_index RIGHT_INDEX_MOD key
  #define RightIndex_layer7(key) right_index RIGHT_INDEX_MOD key
  #define RightIndex_layer8(key) right_index RIGHT_INDEX_MOD key
  #define RightIndex_layer9(key) right_index RIGHT_INDEX_MOD key
  #define RightIndex_layer10(key) right_index RIGHT_INDEX_MOD key
  #ifndef LEFT_RINGY_PINKY_HOLDING_TYPE
  #define LEFT_RINGY_PINKY_HOLDING_TYPE LEFT_RINGY_CHORD_HOLDING_TYPE
  #endif
  #ifndef LEFT_RINGY_PINKY_HOLDING_TIME
  #define LEFT_RINGY_PINKY_HOLDING_TIME LEFT_RINGY_CHORD_HOLDING_TIME
  #endif
  #ifndef LEFT_RINGY_PINKY_STREAK_DECAY
  #define LEFT_RINGY_PINKY_STREAK_DECAY LEFT_RINGY_CHORD_STREAK_DECAY
  #endif
  left_ringy_pinky: homey_left_ringy_pinky {
    compatible = "zmk,behavior-hold-tap";
    flavor = LEFT_RINGY_HOLDING_TYPE;
    hold-trigger-key-positions = <RIGHT_HAND_KEYS THUMB_KEYS>;
    hold-trigger-on-release; // wait for other home row mods
    tapping-term-ms = <LEFT_RINGY_HOLDING_TIME>;
    require-prior-idle-ms = <LEFT_RINGY_STREAK_DECAY>;
    #binding-cells = <2>;
    bindings = <&kp>, <&kp>;
  };
  left_ringy_pinky_bilateral: homey_left_ringy_pinky_bilateral {
    compatible = "zmk,behavior-hold-tap";
    flavor = LEFT_RINGY_HOLDING_TYPE;
    hold-trigger-key-positions = <RIGHT_HAND_KEYS THUMB_KEYS>;
    hold-trigger-on-release; // wait for other home row mods
    tapping-term-ms = <LEFT_RINGY_HOLDING_TIME>;
    require-prior-idle-ms = <LEFT_RINGY_STREAK_DECAY>;
    #binding-cells = <2>;
    bindings = <&kp>, <&left_ringy_tap>;
  };
  #define LeftRingyPinky left_ringy_pinky_bilateral LEFT_PINKY_MOD LEFT_PINKY_KEY
  #ifndef LEFT_MIDDY_PINKY_HOLDING_TYPE
  #define LEFT_MIDDY_PINKY_HOLDING_TYPE LEFT_MIDDY_CHORD_HOLDING_TYPE
  #endif
  #ifndef LEFT_MIDDY_PINKY_HOLDING_TIME
  #define LEFT_MIDDY_PINKY_HOLDING_TIME LEFT_MIDDY_CHORD_HOLDING_TIME
  #endif
  #ifndef LEFT_MIDDY_PINKY_STREAK_DECAY
  #define LEFT_MIDDY_PINKY_STREAK_DECAY LEFT_MIDDY_CHORD_STREAK_DECAY
  #endif
  left_middy_pinky: homey_left_middy_pinky {
    compatible = "zmk,behavior-hold-tap";
    flavor = LEFT_MIDDY_HOLDING_TYPE;
    hold-trigger-key-positions = <RIGHT_HAND_KEYS THUMB_KEYS>;
    hold-trigger-on-release; // wait for other home row mods
    tapping-term-ms = <LEFT_MIDDY_HOLDING_TIME>;
    require-prior-idle-ms = <LEFT_MIDDY_STREAK_DECAY>;
    #binding-cells = <2>;
    bindings = <&kp>, <&kp>;
  };
  left_middy_pinky_bilateral: homey_left_middy_pinky_bilateral {
    compatible = "zmk,behavior-hold-tap";
    flavor = LEFT_MIDDY_HOLDING_TYPE;
    hold-trigger-key-positions = <RIGHT_HAND_KEYS THUMB_KEYS>;
    hold-trigger-on-release; // wait for other home row mods
    tapping-term-ms = <LEFT_MIDDY_HOLDING_TIME>;
    require-prior-idle-ms = <LEFT_MIDDY_STREAK_DECAY>;
    #binding-cells = <2>;
    bindings = <&kp>, <&left_middy_tap>;
  };
  #define LeftMiddyPinky left_middy_pinky_bilateral LEFT_PINKY_MOD LEFT_PINKY_KEY
  #ifndef LEFT_INDEX_PINKY_HOLDING_TYPE
  #define LEFT_INDEX_PINKY_HOLDING_TYPE LEFT_INDEX_CHORD_HOLDING_TYPE
  #endif
  #ifndef LEFT_INDEX_PINKY_HOLDING_TIME
  #define LEFT_INDEX_PINKY_HOLDING_TIME LEFT_INDEX_CHORD_HOLDING_TIME
  #endif
  #ifndef LEFT_INDEX_PINKY_STREAK_DECAY
  #define LEFT_INDEX_PINKY_STREAK_DECAY LEFT_INDEX_CHORD_STREAK_DECAY
  #endif
  left_index_pinky: homey_left_index_pinky {
    compatible = "zmk,behavior-hold-tap";
    flavor = LEFT_INDEX_HOLDING_TYPE;
    hold-trigger-key-positions = <RIGHT_HAND_KEYS THUMB_KEYS>;
    hold-trigger-on-release; // wait for other home row mods
    tapping-term-ms = <LEFT_INDEX_HOLDING_TIME>;
    require-prior-idle-ms = <LEFT_INDEX_STREAK_DECAY>;
    #binding-cells = <2>;
    bindings = <&kp>, <&kp>;
  };
  left_index_pinky_bilateral: homey_left_index_pinky_bilateral {
    compatible = "zmk,behavior-hold-tap";
    flavor = LEFT_INDEX_HOLDING_TYPE;
    hold-trigger-key-positions = <RIGHT_HAND_KEYS THUMB_KEYS>;
    hold-trigger-on-release; // wait for other home row mods
    tapping-term-ms = <LEFT_INDEX_HOLDING_TIME>;
    require-prior-idle-ms = <LEFT_INDEX_STREAK_DECAY>;
    #binding-cells = <2>;
    bindings = <&kp>, <&left_index_tap>;
  };
  #define LeftIndexPinky left_index_pinky_bilateral LEFT_PINKY_MOD LEFT_PINKY_KEY
  #ifndef RIGHT_RINGY_PINKY_HOLDING_TYPE
  #define RIGHT_RINGY_PINKY_HOLDING_TYPE RIGHT_RINGY_CHORD_HOLDING_TYPE
  #endif
  #ifndef RIGHT_RINGY_PINKY_HOLDING_TIME
  #define RIGHT_RINGY_PINKY_HOLDING_TIME RIGHT_RINGY_CHORD_HOLDING_TIME
  #endif
  #ifndef RIGHT_RINGY_PINKY_STREAK_DECAY
  #define RIGHT_RINGY_PINKY_STREAK_DECAY RIGHT_RINGY_CHORD_STREAK_DECAY
  #endif
  right_ringy_pinky: homey_right_ringy_pinky {
    compatible = "zmk,behavior-hold-tap";
    flavor = RIGHT_RINGY_HOLDING_TYPE;
    hold-trigger-key-positions = <LEFT_HAND_KEYS THUMB_KEYS>;
    hold-trigger-on-release; // wait for other home row mods
    tapping-term-ms = <RIGHT_RINGY_HOLDING_TIME>;
    require-prior-idle-ms = <RIGHT_RINGY_STREAK_DECAY>;
    #binding-cells = <2>;
    bindings = <&kp>, <&kp>;
  };
  right_ringy_pinky_bilateral: homey_right_ringy_pinky_bilateral {
    compatible = "zmk,behavior-hold-tap";
    flavor = RIGHT_RINGY_HOLDING_TYPE;
    hold-trigger-key-positions = <LEFT_HAND_KEYS THUMB_KEYS>;
    hold-trigger-on-release; // wait for other home row mods
    tapping-term-ms = <RIGHT_RINGY_HOLDING_TIME>;
    require-prior-idle-ms = <RIGHT_RINGY_STREAK_DECAY>;
    #binding-cells = <2>;
    bindings = <&kp>, <&right_ringy_tap>;
  };
  #define RightRingyPinky right_ringy_pinky_bilateral RIGHT_PINKY_MOD RIGHT_PINKY_KEY
  #ifndef RIGHT_MIDDY_PINKY_HOLDING_TYPE
  #define RIGHT_MIDDY_PINKY_HOLDING_TYPE RIGHT_MIDDY_CHORD_HOLDING_TYPE
  #endif
  #ifndef RIGHT_MIDDY_PINKY_HOLDING_TIME
  #define RIGHT_MIDDY_PINKY_HOLDING_TIME RIGHT_MIDDY_CHORD_HOLDING_TIME
  #endif
  #ifndef RIGHT_MIDDY_PINKY_STREAK_DECAY
  #define RIGHT_MIDDY_PINKY_STREAK_DECAY RIGHT_MIDDY_CHORD_STREAK_DECAY
  #endif
  right_middy_pinky: homey_right_middy_pinky {
    compatible = "zmk,behavior-hold-tap";
    flavor = RIGHT_MIDDY_HOLDING_TYPE;
    hold-trigger-key-positions = <LEFT_HAND_KEYS THUMB_KEYS>;
    hold-trigger-on-release; // wait for other home row mods
    tapping-term-ms = <RIGHT_MIDDY_HOLDING_TIME>;
    require-prior-idle-ms = <RIGHT_MIDDY_STREAK_DECAY>;
    #binding-cells = <2>;
    bindings = <&kp>, <&kp>;
  };
  right_middy_pinky_bilateral: homey_right_middy_pinky_bilateral {
    compatible = "zmk,behavior-hold-tap";
    flavor = RIGHT_MIDDY_HOLDING_TYPE;
    hold-trigger-key-positions = <LEFT_HAND_KEYS THUMB_KEYS>;
    hold-trigger-on-release; // wait for other home row mods
    tapping-term-ms = <RIGHT_MIDDY_HOLDING_TIME>;
    require-prior-idle-ms = <RIGHT_MIDDY_STREAK_DECAY>;
    #binding-cells = <2>;
    bindings = <&kp>, <&right_middy_tap>;
  };
  #define RightMiddyPinky right_middy_pinky_bilateral RIGHT_PINKY_MOD RIGHT_PINKY_KEY
  #ifndef RIGHT_INDEX_PINKY_HOLDING_TYPE
  #define RIGHT_INDEX_PINKY_HOLDING_TYPE RIGHT_INDEX_CHORD_HOLDING_TYPE
  #endif
  #ifndef RIGHT_INDEX_PINKY_HOLDING_TIME
  #define RIGHT_INDEX_PINKY_HOLDING_TIME RIGHT_INDEX_CHORD_HOLDING_TIME
  #endif
  #ifndef RIGHT_INDEX_PINKY_STREAK_DECAY
  #define RIGHT_INDEX_PINKY_STREAK_DECAY RIGHT_INDEX_CHORD_STREAK_DECAY
  #endif
  right_index_pinky: homey_right_index_pinky {
    compatible = "zmk,behavior-hold-tap";
    flavor = RIGHT_INDEX_HOLDING_TYPE;
    hold-trigger-key-positions = <LEFT_HAND_KEYS THUMB_KEYS>;
    hold-trigger-on-release; // wait for other home row mods
    tapping-term-ms = <RIGHT_INDEX_HOLDING_TIME>;
    require-prior-idle-ms = <RIGHT_INDEX_STREAK_DECAY>;
    #binding-cells = <2>;
    bindings = <&kp>, <&kp>;
  };
  right_index_pinky_bilateral: homey_right_index_pinky_bilateral {
    compatible = "zmk,behavior-hold-tap";
    flavor = RIGHT_INDEX_HOLDING_TYPE;
    hold-trigger-key-positions = <LEFT_HAND_KEYS THUMB_KEYS>;
    hold-trigger-on-release; // wait for other home row mods
    tapping-term-ms = <RIGHT_INDEX_HOLDING_TIME>;
    require-prior-idle-ms = <RIGHT_INDEX_STREAK_DECAY>;
    #binding-cells = <2>;
    bindings = <&kp>, <&right_index_tap>;
  };
  #define RightIndexPinky right_index_pinky_bilateral RIGHT_PINKY_MOD RIGHT_PINKY_KEY
  #ifndef LEFT_PINKY_RINGY_HOLDING_TYPE
  #define LEFT_PINKY_RINGY_HOLDING_TYPE LEFT_PINKY_CHORD_HOLDING_TYPE
  #endif
  #ifndef LEFT_PINKY_RINGY_HOLDING_TIME
  #define LEFT_PINKY_RINGY_HOLDING_TIME LEFT_PINKY_CHORD_HOLDING_TIME
  #endif
  #ifndef LEFT_PINKY_RINGY_STREAK_DECAY
  #define LEFT_PINKY_RINGY_STREAK_DECAY LEFT_PINKY_CHORD_STREAK_DECAY
  #endif
  left_pinky_ringy: homey_left_pinky_ringy {
    compatible = "zmk,behavior-hold-tap";
    flavor = LEFT_PINKY_HOLDING_TYPE;
    hold-trigger-key-positions = <RIGHT_HAND_KEYS THUMB_KEYS>;
    hold-trigger-on-release; // wait for other home row mods
    tapping-term-ms = <LEFT_PINKY_HOLDING_TIME>;
    require-prior-idle-ms = <LEFT_PINKY_STREAK_DECAY>;
    #binding-cells = <2>;
    bindings = <&kp>, <&kp>;
  };
  left_pinky_ringy_bilateral: homey_left_pinky_ringy_bilateral {
    compatible = "zmk,behavior-hold-tap";
    flavor = LEFT_PINKY_HOLDING_TYPE;
    hold-trigger-key-positions = <RIGHT_HAND_KEYS THUMB_KEYS>;
    hold-trigger-on-release; // wait for other home row mods
    tapping-term-ms = <LEFT_PINKY_HOLDING_TIME>;
    require-prior-idle-ms = <LEFT_PINKY_STREAK_DECAY>;
    #binding-cells = <2>;
    bindings = <&kp>, <&left_pinky_tap>;
  };
  #define LeftPinkyRingy left_pinky_ringy_bilateral LEFT_RINGY_MOD LEFT_RINGY_KEY
  #ifndef LEFT_MIDDY_RINGY_HOLDING_TYPE
  #define LEFT_MIDDY_RINGY_HOLDING_TYPE LEFT_MIDDY_CHORD_HOLDING_TYPE
  #endif
  #ifndef LEFT_MIDDY_RINGY_HOLDING_TIME
  #define LEFT_MIDDY_RINGY_HOLDING_TIME LEFT_MIDDY_CHORD_HOLDING_TIME
  #endif
  #ifndef LEFT_MIDDY_RINGY_STREAK_DECAY
  #define LEFT_MIDDY_RINGY_STREAK_DECAY LEFT_MIDDY_CHORD_STREAK_DECAY
  #endif
  left_middy_ringy: homey_left_middy_ringy {
    compatible = "zmk,behavior-hold-tap";
    flavor = LEFT_MIDDY_HOLDING_TYPE;
    hold-trigger-key-positions = <RIGHT_HAND_KEYS THUMB_KEYS>;
    hold-trigger-on-release; // wait for other home row mods
    tapping-term-ms = <LEFT_MIDDY_HOLDING_TIME>;
    require-prior-idle-ms = <LEFT_MIDDY_STREAK_DECAY>;
    #binding-cells = <2>;
    bindings = <&kp>, <&kp>;
  };
  left_middy_ringy_bilateral: homey_left_middy_ringy_bilateral {
    compatible = "zmk,behavior-hold-tap";
    flavor = LEFT_MIDDY_HOLDING_TYPE;
    hold-trigger-key-positions = <RIGHT_HAND_KEYS THUMB_KEYS>;
    hold-trigger-on-release; // wait for other home row mods
    tapping-term-ms = <LEFT_MIDDY_HOLDING_TIME>;
    require-prior-idle-ms = <LEFT_MIDDY_STREAK_DECAY>;
    #binding-cells = <2>;
    bindings = <&kp>, <&left_middy_tap>;
  };
  #define LeftMiddyRingy left_middy_ringy_bilateral LEFT_RINGY_MOD LEFT_RINGY_KEY
  #ifndef LEFT_INDEX_RINGY_HOLDING_TYPE
  #define LEFT_INDEX_RINGY_HOLDING_TYPE LEFT_INDEX_CHORD_HOLDING_TYPE
  #endif
  #ifndef LEFT_INDEX_RINGY_HOLDING_TIME
  #define LEFT_INDEX_RINGY_HOLDING_TIME LEFT_INDEX_CHORD_HOLDING_TIME
  #endif
  #ifndef LEFT_INDEX_RINGY_STREAK_DECAY
  #define LEFT_INDEX_RINGY_STREAK_DECAY LEFT_INDEX_CHORD_STREAK_DECAY
  #endif
  left_index_ringy: homey_left_index_ringy {
    compatible = "zmk,behavior-hold-tap";
    flavor = LEFT_INDEX_HOLDING_TYPE;
    hold-trigger-key-positions = <RIGHT_HAND_KEYS THUMB_KEYS>;
    hold-trigger-on-release; // wait for other home row mods
    tapping-term-ms = <LEFT_INDEX_HOLDING_TIME>;
    require-prior-idle-ms = <LEFT_INDEX_STREAK_DECAY>;
    #binding-cells = <2>;
    bindings = <&kp>, <&kp>;
  };
  left_index_ringy_bilateral: homey_left_index_ringy_bilateral {
    compatible = "zmk,behavior-hold-tap";
    flavor = LEFT_INDEX_HOLDING_TYPE;
    hold-trigger-key-positions = <RIGHT_HAND_KEYS THUMB_KEYS>;
    hold-trigger-on-release; // wait for other home row mods
    tapping-term-ms = <LEFT_INDEX_HOLDING_TIME>;
    require-prior-idle-ms = <LEFT_INDEX_STREAK_DECAY>;
    #binding-cells = <2>;
    bindings = <&kp>, <&left_index_tap>;
  };
  #define LeftIndexRingy left_index_ringy_bilateral LEFT_RINGY_MOD LEFT_RINGY_KEY
  #ifndef RIGHT_PINKY_RINGY_HOLDING_TYPE
  #define RIGHT_PINKY_RINGY_HOLDING_TYPE RIGHT_PINKY_CHORD_HOLDING_TYPE
  #endif
  #ifndef RIGHT_PINKY_RINGY_HOLDING_TIME
  #define RIGHT_PINKY_RINGY_HOLDING_TIME RIGHT_PINKY_CHORD_HOLDING_TIME
  #endif
  #ifndef RIGHT_PINKY_RINGY_STREAK_DECAY
  #define RIGHT_PINKY_RINGY_STREAK_DECAY RIGHT_PINKY_CHORD_STREAK_DECAY
  #endif
  right_pinky_ringy: homey_right_pinky_ringy {
    compatible = "zmk,behavior-hold-tap";
    flavor = RIGHT_PINKY_HOLDING_TYPE;
    hold-trigger-key-positions = <LEFT_HAND_KEYS THUMB_KEYS>;
    hold-trigger-on-release; // wait for other home row mods
    tapping-term-ms = <RIGHT_PINKY_HOLDING_TIME>;
    require-prior-idle-ms = <RIGHT_PINKY_STREAK_DECAY>;
    #binding-cells = <2>;
    bindings = <&kp>, <&kp>;
  };
  right_pinky_ringy_bilateral: homey_right_pinky_ringy_bilateral {
    compatible = "zmk,behavior-hold-tap";
    flavor = RIGHT_PINKY_HOLDING_TYPE;
    hold-trigger-key-positions = <LEFT_HAND_KEYS THUMB_KEYS>;
    hold-trigger-on-release; // wait for other home row mods
    tapping-term-ms = <RIGHT_PINKY_HOLDING_TIME>;
    require-prior-idle-ms = <RIGHT_PINKY_STREAK_DECAY>;
    #binding-cells = <2>;
    bindings = <&kp>, <&right_pinky_tap>;
  };
  #define RightPinkyRingy right_pinky_ringy_bilateral RIGHT_RINGY_MOD RIGHT_RINGY_KEY
  #ifndef RIGHT_MIDDY_RINGY_HOLDING_TYPE
  #define RIGHT_MIDDY_RINGY_HOLDING_TYPE RIGHT_MIDDY_CHORD_HOLDING_TYPE
  #endif
  #ifndef RIGHT_MIDDY_RINGY_HOLDING_TIME
  #define RIGHT_MIDDY_RINGY_HOLDING_TIME RIGHT_MIDDY_CHORD_HOLDING_TIME
  #endif
  #ifndef RIGHT_MIDDY_RINGY_STREAK_DECAY
  #define RIGHT_MIDDY_RINGY_STREAK_DECAY RIGHT_MIDDY_CHORD_STREAK_DECAY
  #endif
  right_middy_ringy: homey_right_middy_ringy {
    compatible = "zmk,behavior-hold-tap";
    flavor = RIGHT_MIDDY_HOLDING_TYPE;
    hold-trigger-key-positions = <LEFT_HAND_KEYS THUMB_KEYS>;
    hold-trigger-on-release; // wait for other home row mods
    tapping-term-ms = <RIGHT_MIDDY_HOLDING_TIME>;
    require-prior-idle-ms = <RIGHT_MIDDY_STREAK_DECAY>;
    #binding-cells = <2>;
    bindings = <&kp>, <&kp>;
  };
  right_middy_ringy_bilateral: homey_right_middy_ringy_bilateral {
    compatible = "zmk,behavior-hold-tap";
    flavor = RIGHT_MIDDY_HOLDING_TYPE;
    hold-trigger-key-positions = <LEFT_HAND_KEYS THUMB_KEYS>;
    hold-trigger-on-release; // wait for other home row mods
    tapping-term-ms = <RIGHT_MIDDY_HOLDING_TIME>;
    require-prior-idle-ms = <RIGHT_MIDDY_STREAK_DECAY>;
    #binding-cells = <2>;
    bindings = <&kp>, <&right_middy_tap>;
  };
  #define RightMiddyRingy right_middy_ringy_bilateral RIGHT_RINGY_MOD RIGHT_RINGY_KEY
  #ifndef RIGHT_INDEX_RINGY_HOLDING_TYPE
  #define RIGHT_INDEX_RINGY_HOLDING_TYPE RIGHT_INDEX_CHORD_HOLDING_TYPE
  #endif
  #ifndef RIGHT_INDEX_RINGY_HOLDING_TIME
  #define RIGHT_INDEX_RINGY_HOLDING_TIME RIGHT_INDEX_CHORD_HOLDING_TIME
  #endif
  #ifndef RIGHT_INDEX_RINGY_STREAK_DECAY
  #define RIGHT_INDEX_RINGY_STREAK_DECAY RIGHT_INDEX_CHORD_STREAK_DECAY
  #endif
  right_index_ringy: homey_right_index_ringy {
    compatible = "zmk,behavior-hold-tap";
    flavor = RIGHT_INDEX_HOLDING_TYPE;
    hold-trigger-key-positions = <LEFT_HAND_KEYS THUMB_KEYS>;
    hold-trigger-on-release; // wait for other home row mods
    tapping-term-ms = <RIGHT_INDEX_HOLDING_TIME>;
    require-prior-idle-ms = <RIGHT_INDEX_STREAK_DECAY>;
    #binding-cells = <2>;
    bindings = <&kp>, <&kp>;
  };
  right_index_ringy_bilateral: homey_right_index_ringy_bilateral {
    compatible = "zmk,behavior-hold-tap";
    flavor = RIGHT_INDEX_HOLDING_TYPE;
    hold-trigger-key-positions = <LEFT_HAND_KEYS THUMB_KEYS>;
    hold-trigger-on-release; // wait for other home row mods
    tapping-term-ms = <RIGHT_INDEX_HOLDING_TIME>;
    require-prior-idle-ms = <RIGHT_INDEX_STREAK_DECAY>;
    #binding-cells = <2>;
    bindings = <&kp>, <&right_index_tap>;
  };
  #define RightIndexRingy right_index_ringy_bilateral RIGHT_RINGY_MOD RIGHT_RINGY_KEY
  #ifndef LEFT_PINKY_MIDDY_HOLDING_TYPE
  #define LEFT_PINKY_MIDDY_HOLDING_TYPE LEFT_PINKY_CHORD_HOLDING_TYPE
  #endif
  #ifndef LEFT_PINKY_MIDDY_HOLDING_TIME
  #define LEFT_PINKY_MIDDY_HOLDING_TIME LEFT_PINKY_CHORD_HOLDING_TIME
  #endif
  #ifndef LEFT_PINKY_MIDDY_STREAK_DECAY
  #define LEFT_PINKY_MIDDY_STREAK_DECAY LEFT_PINKY_CHORD_STREAK_DECAY
  #endif
  left_pinky_middy: homey_left_pinky_middy {
    compatible = "zmk,behavior-hold-tap";
    flavor = LEFT_PINKY_HOLDING_TYPE;
    hold-trigger-key-positions = <RIGHT_HAND_KEYS THUMB_KEYS>;
    hold-trigger-on-release; // wait for other home row mods
    tapping-term-ms = <LEFT_PINKY_HOLDING_TIME>;
    require-prior-idle-ms = <LEFT_PINKY_STREAK_DECAY>;
    #binding-cells = <2>;
    bindings = <&kp>, <&kp>;
  };
  left_pinky_middy_bilateral: homey_left_pinky_middy_bilateral {
    compatible = "zmk,behavior-hold-tap";
    flavor = LEFT_PINKY_HOLDING_TYPE;
    hold-trigger-key-positions = <RIGHT_HAND_KEYS THUMB_KEYS>;
    hold-trigger-on-release; // wait for other home row mods
    tapping-term-ms = <LEFT_PINKY_HOLDING_TIME>;
    require-prior-idle-ms = <LEFT_PINKY_STREAK_DECAY>;
    #binding-cells = <2>;
    bindings = <&kp>, <&left_pinky_tap>;
  };
  #define LeftPinkyMiddy left_pinky_middy_bilateral LEFT_MIDDY_MOD LEFT_MIDDY_KEY
  #ifndef LEFT_RINGY_MIDDY_HOLDING_TYPE
  #define LEFT_RINGY_MIDDY_HOLDING_TYPE LEFT_RINGY_CHORD_HOLDING_TYPE
  #endif
  #ifndef LEFT_RINGY_MIDDY_HOLDING_TIME
  #define LEFT_RINGY_MIDDY_HOLDING_TIME LEFT_RINGY_CHORD_HOLDING_TIME
  #endif
  #ifndef LEFT_RINGY_MIDDY_STREAK_DECAY
  #define LEFT_RINGY_MIDDY_STREAK_DECAY LEFT_RINGY_CHORD_STREAK_DECAY
  #endif
  left_ringy_middy: homey_left_ringy_middy {
    compatible = "zmk,behavior-hold-tap";
    flavor = LEFT_RINGY_HOLDING_TYPE;
    hold-trigger-key-positions = <RIGHT_HAND_KEYS THUMB_KEYS>;
    hold-trigger-on-release; // wait for other home row mods
    tapping-term-ms = <LEFT_RINGY_HOLDING_TIME>;
    require-prior-idle-ms = <LEFT_RINGY_STREAK_DECAY>;
    #binding-cells = <2>;
    bindings = <&kp>, <&kp>;
  };
  left_ringy_middy_bilateral: homey_left_ringy_middy_bilateral {
    compatible = "zmk,behavior-hold-tap";
    flavor = LEFT_RINGY_HOLDING_TYPE;
    hold-trigger-key-positions = <RIGHT_HAND_KEYS THUMB_KEYS>;
    hold-trigger-on-release; // wait for other home row mods
    tapping-term-ms = <LEFT_RINGY_HOLDING_TIME>;
    require-prior-idle-ms = <LEFT_RINGY_STREAK_DECAY>;
    #binding-cells = <2>;
    bindings = <&kp>, <&left_ringy_tap>;
  };
  #define LeftRingyMiddy left_ringy_middy_bilateral LEFT_MIDDY_MOD LEFT_MIDDY_KEY
  #ifndef LEFT_INDEX_MIDDY_HOLDING_TYPE
  #define LEFT_INDEX_MIDDY_HOLDING_TYPE LEFT_INDEX_CHORD_HOLDING_TYPE
  #endif
  #ifndef LEFT_INDEX_MIDDY_HOLDING_TIME
  #define LEFT_INDEX_MIDDY_HOLDING_TIME LEFT_INDEX_CHORD_HOLDING_TIME
  #endif
  #ifndef LEFT_INDEX_MIDDY_STREAK_DECAY
  #define LEFT_INDEX_MIDDY_STREAK_DECAY LEFT_INDEX_CHORD_STREAK_DECAY
  #endif
  left_index_middy: homey_left_index_middy {
    compatible = "zmk,behavior-hold-tap";
    flavor = LEFT_INDEX_HOLDING_TYPE;
    hold-trigger-key-positions = <RIGHT_HAND_KEYS THUMB_KEYS>;
    hold-trigger-on-release; // wait for other home row mods
    tapping-term-ms = <LEFT_INDEX_HOLDING_TIME>;
    require-prior-idle-ms = <LEFT_INDEX_STREAK_DECAY>;
    #binding-cells = <2>;
    bindings = <&kp>, <&kp>;
  };
  left_index_middy_bilateral: homey_left_index_middy_bilateral {
    compatible = "zmk,behavior-hold-tap";
    flavor = LEFT_INDEX_HOLDING_TYPE;
    hold-trigger-key-positions = <RIGHT_HAND_KEYS THUMB_KEYS>;
    hold-trigger-on-release; // wait for other home row mods
    tapping-term-ms = <LEFT_INDEX_HOLDING_TIME>;
    require-prior-idle-ms = <LEFT_INDEX_STREAK_DECAY>;
    #binding-cells = <2>;
    bindings = <&kp>, <&left_index_tap>;
  };
  #define LeftIndexMiddy left_index_middy_bilateral LEFT_MIDDY_MOD LEFT_MIDDY_KEY
  #ifndef RIGHT_PINKY_MIDDY_HOLDING_TYPE
  #define RIGHT_PINKY_MIDDY_HOLDING_TYPE RIGHT_PINKY_CHORD_HOLDING_TYPE
  #endif
  #ifndef RIGHT_PINKY_MIDDY_HOLDING_TIME
  #define RIGHT_PINKY_MIDDY_HOLDING_TIME RIGHT_PINKY_CHORD_HOLDING_TIME
  #endif
  #ifndef RIGHT_PINKY_MIDDY_STREAK_DECAY
  #define RIGHT_PINKY_MIDDY_STREAK_DECAY RIGHT_PINKY_CHORD_STREAK_DECAY
  #endif
  right_pinky_middy: homey_right_pinky_middy {
    compatible = "zmk,behavior-hold-tap";
    flavor = RIGHT_PINKY_HOLDING_TYPE;
    hold-trigger-key-positions = <LEFT_HAND_KEYS THUMB_KEYS>;
    hold-trigger-on-release; // wait for other home row mods
    tapping-term-ms = <RIGHT_PINKY_HOLDING_TIME>;
    require-prior-idle-ms = <RIGHT_PINKY_STREAK_DECAY>;
    #binding-cells = <2>;
    bindings = <&kp>, <&kp>;
  };
  right_pinky_middy_bilateral: homey_right_pinky_middy_bilateral {
    compatible = "zmk,behavior-hold-tap";
    flavor = RIGHT_PINKY_HOLDING_TYPE;
    hold-trigger-key-positions = <LEFT_HAND_KEYS THUMB_KEYS>;
    hold-trigger-on-release; // wait for other home row mods
    tapping-term-ms = <RIGHT_PINKY_HOLDING_TIME>;
    require-prior-idle-ms = <RIGHT_PINKY_STREAK_DECAY>;
    #binding-cells = <2>;
    bindings = <&kp>, <&right_pinky_tap>;
  };
  #define RightPinkyMiddy right_pinky_middy_bilateral RIGHT_MIDDY_MOD RIGHT_MIDDY_KEY
  #ifndef RIGHT_RINGY_MIDDY_HOLDING_TYPE
  #define RIGHT_RINGY_MIDDY_HOLDING_TYPE RIGHT_RINGY_CHORD_HOLDING_TYPE
  #endif
  #ifndef RIGHT_RINGY_MIDDY_HOLDING_TIME
  #define RIGHT_RINGY_MIDDY_HOLDING_TIME RIGHT_RINGY_CHORD_HOLDING_TIME
  #endif
  #ifndef RIGHT_RINGY_MIDDY_STREAK_DECAY
  #define RIGHT_RINGY_MIDDY_STREAK_DECAY RIGHT_RINGY_CHORD_STREAK_DECAY
  #endif
  right_ringy_middy: homey_right_ringy_middy {
    compatible = "zmk,behavior-hold-tap";
    flavor = RIGHT_RINGY_HOLDING_TYPE;
    hold-trigger-key-positions = <LEFT_HAND_KEYS THUMB_KEYS>;
    hold-trigger-on-release; // wait for other home row mods
    tapping-term-ms = <RIGHT_RINGY_HOLDING_TIME>;
    require-prior-idle-ms = <RIGHT_RINGY_STREAK_DECAY>;
    #binding-cells = <2>;
    bindings = <&kp>, <&kp>;
  };
  right_ringy_middy_bilateral: homey_right_ringy_middy_bilateral {
    compatible = "zmk,behavior-hold-tap";
    flavor = RIGHT_RINGY_HOLDING_TYPE;
    hold-trigger-key-positions = <LEFT_HAND_KEYS THUMB_KEYS>;
    hold-trigger-on-release; // wait for other home row mods
    tapping-term-ms = <RIGHT_RINGY_HOLDING_TIME>;
    require-prior-idle-ms = <RIGHT_RINGY_STREAK_DECAY>;
    #binding-cells = <2>;
    bindings = <&kp>, <&right_ringy_tap>;
  };
  #define RightRingyMiddy right_ringy_middy_bilateral RIGHT_MIDDY_MOD RIGHT_MIDDY_KEY
  #ifndef RIGHT_INDEX_MIDDY_HOLDING_TYPE
  #define RIGHT_INDEX_MIDDY_HOLDING_TYPE RIGHT_INDEX_CHORD_HOLDING_TYPE
  #endif
  #ifndef RIGHT_INDEX_MIDDY_HOLDING_TIME
  #define RIGHT_INDEX_MIDDY_HOLDING_TIME RIGHT_INDEX_CHORD_HOLDING_TIME
  #endif
  #ifndef RIGHT_INDEX_MIDDY_STREAK_DECAY
  #define RIGHT_INDEX_MIDDY_STREAK_DECAY RIGHT_INDEX_CHORD_STREAK_DECAY
  #endif
  right_index_middy: homey_right_index_middy {
    compatible = "zmk,behavior-hold-tap";
    flavor = RIGHT_INDEX_HOLDING_TYPE;
    hold-trigger-key-positions = <LEFT_HAND_KEYS THUMB_KEYS>;
    hold-trigger-on-release; // wait for other home row mods
    tapping-term-ms = <RIGHT_INDEX_HOLDING_TIME>;
    require-prior-idle-ms = <RIGHT_INDEX_STREAK_DECAY>;
    #binding-cells = <2>;
    bindings = <&kp>, <&kp>;
  };
  right_index_middy_bilateral: homey_right_index_middy_bilateral {
    compatible = "zmk,behavior-hold-tap";
    flavor = RIGHT_INDEX_HOLDING_TYPE;
    hold-trigger-key-positions = <LEFT_HAND_KEYS THUMB_KEYS>;
    hold-trigger-on-release; // wait for other home row mods
    tapping-term-ms = <RIGHT_INDEX_HOLDING_TIME>;
    require-prior-idle-ms = <RIGHT_INDEX_STREAK_DECAY>;
    #binding-cells = <2>;
    bindings = <&kp>, <&right_index_tap>;
  };
  #define RightIndexMiddy right_index_middy_bilateral RIGHT_MIDDY_MOD RIGHT_MIDDY_KEY
  #ifndef LEFT_PINKY_INDEX_HOLDING_TYPE
  #define LEFT_PINKY_INDEX_HOLDING_TYPE LEFT_PINKY_CHORD_HOLDING_TYPE
  #endif
  #ifndef LEFT_PINKY_INDEX_HOLDING_TIME
  #define LEFT_PINKY_INDEX_HOLDING_TIME LEFT_PINKY_CHORD_HOLDING_TIME
  #endif
  #ifndef LEFT_PINKY_INDEX_STREAK_DECAY
  #define LEFT_PINKY_INDEX_STREAK_DECAY LEFT_PINKY_CHORD_STREAK_DECAY
  #endif
  left_pinky_index: homey_left_pinky_index {
    compatible = "zmk,behavior-hold-tap";
    flavor = LEFT_PINKY_HOLDING_TYPE;
    hold-trigger-key-positions = <RIGHT_HAND_KEYS THUMB_KEYS>;
    hold-trigger-on-release; // wait for other home row mods
    tapping-term-ms = <LEFT_PINKY_HOLDING_TIME>;
    require-prior-idle-ms = <LEFT_PINKY_STREAK_DECAY>;
    #binding-cells = <2>;
    bindings = <&kp>, <&kp>;
  };
  left_pinky_index_bilateral: homey_left_pinky_index_bilateral {
    compatible = "zmk,behavior-hold-tap";
    flavor = LEFT_PINKY_HOLDING_TYPE;
    hold-trigger-key-positions = <RIGHT_HAND_KEYS THUMB_KEYS>;
    hold-trigger-on-release; // wait for other home row mods
    tapping-term-ms = <LEFT_PINKY_HOLDING_TIME>;
    require-prior-idle-ms = <LEFT_PINKY_STREAK_DECAY>;
    #binding-cells = <2>;
    bindings = <&kp>, <&left_pinky_tap>;
  };
  #define LeftPinkyIndex left_pinky_index_bilateral LEFT_INDEX_MOD LEFT_INDEX_KEY
  #ifndef LEFT_RINGY_INDEX_HOLDING_TYPE
  #define LEFT_RINGY_INDEX_HOLDING_TYPE LEFT_RINGY_CHORD_HOLDING_TYPE
  #endif
  #ifndef LEFT_RINGY_INDEX_HOLDING_TIME
  #define LEFT_RINGY_INDEX_HOLDING_TIME LEFT_RINGY_CHORD_HOLDING_TIME
  #endif
  #ifndef LEFT_RINGY_INDEX_STREAK_DECAY
  #define LEFT_RINGY_INDEX_STREAK_DECAY LEFT_RINGY_CHORD_STREAK_DECAY
  #endif
  left_ringy_index: homey_left_ringy_index {
    compatible = "zmk,behavior-hold-tap";
    flavor = LEFT_RINGY_HOLDING_TYPE;
    hold-trigger-key-positions = <RIGHT_HAND_KEYS THUMB_KEYS>;
    hold-trigger-on-release; // wait for other home row mods
    tapping-term-ms = <LEFT_RINGY_HOLDING_TIME>;
    require-prior-idle-ms = <LEFT_RINGY_STREAK_DECAY>;
    #binding-cells = <2>;
    bindings = <&kp>, <&kp>;
  };
  left_ringy_index_bilateral: homey_left_ringy_index_bilateral {
    compatible = "zmk,behavior-hold-tap";
    flavor = LEFT_RINGY_HOLDING_TYPE;
    hold-trigger-key-positions = <RIGHT_HAND_KEYS THUMB_KEYS>;
    hold-trigger-on-release; // wait for other home row mods
    tapping-term-ms = <LEFT_RINGY_HOLDING_TIME>;
    require-prior-idle-ms = <LEFT_RINGY_STREAK_DECAY>;
    #binding-cells = <2>;
    bindings = <&kp>, <&left_ringy_tap>;
  };
  #define LeftRingyIndex left_ringy_index_bilateral LEFT_INDEX_MOD LEFT_INDEX_KEY
  #ifndef LEFT_MIDDY_INDEX_HOLDING_TYPE
  #define LEFT_MIDDY_INDEX_HOLDING_TYPE LEFT_MIDDY_CHORD_HOLDING_TYPE
  #endif
  #ifndef LEFT_MIDDY_INDEX_HOLDING_TIME
  #define LEFT_MIDDY_INDEX_HOLDING_TIME LEFT_MIDDY_CHORD_HOLDING_TIME
  #endif
  #ifndef LEFT_MIDDY_INDEX_STREAK_DECAY
  #define LEFT_MIDDY_INDEX_STREAK_DECAY LEFT_MIDDY_CHORD_STREAK_DECAY
  #endif
  left_middy_index: homey_left_middy_index {
    compatible = "zmk,behavior-hold-tap";
    flavor = LEFT_MIDDY_HOLDING_TYPE;
    hold-trigger-key-positions = <RIGHT_HAND_KEYS THUMB_KEYS>;
    hold-trigger-on-release; // wait for other home row mods
    tapping-term-ms = <LEFT_MIDDY_HOLDING_TIME>;
    require-prior-idle-ms = <LEFT_MIDDY_STREAK_DECAY>;
    #binding-cells = <2>;
    bindings = <&kp>, <&kp>;
  };
  left_middy_index_bilateral: homey_left_middy_index_bilateral {
    compatible = "zmk,behavior-hold-tap";
    flavor = LEFT_MIDDY_HOLDING_TYPE;
    hold-trigger-key-positions = <RIGHT_HAND_KEYS THUMB_KEYS>;
    hold-trigger-on-release; // wait for other home row mods
    tapping-term-ms = <LEFT_MIDDY_HOLDING_TIME>;
    require-prior-idle-ms = <LEFT_MIDDY_STREAK_DECAY>;
    #binding-cells = <2>;
    bindings = <&kp>, <&left_middy_tap>;
  };
  #define LeftMiddyIndex left_middy_index_bilateral LEFT_INDEX_MOD LEFT_INDEX_KEY
  #ifndef RIGHT_PINKY_INDEX_HOLDING_TYPE
  #define RIGHT_PINKY_INDEX_HOLDING_TYPE RIGHT_PINKY_CHORD_HOLDING_TYPE
  #endif
  #ifndef RIGHT_PINKY_INDEX_HOLDING_TIME
  #define RIGHT_PINKY_INDEX_HOLDING_TIME RIGHT_PINKY_CHORD_HOLDING_TIME
  #endif
  #ifndef RIGHT_PINKY_INDEX_STREAK_DECAY
  #define RIGHT_PINKY_INDEX_STREAK_DECAY RIGHT_PINKY_CHORD_STREAK_DECAY
  #endif
  right_pinky_index: homey_right_pinky_index {
    compatible = "zmk,behavior-hold-tap";
    flavor = RIGHT_PINKY_HOLDING_TYPE;
    hold-trigger-key-positions = <LEFT_HAND_KEYS THUMB_KEYS>;
    hold-trigger-on-release; // wait for other home row mods
    tapping-term-ms = <RIGHT_PINKY_HOLDING_TIME>;
    require-prior-idle-ms = <RIGHT_PINKY_STREAK_DECAY>;
    #binding-cells = <2>;
    bindings = <&kp>, <&kp>;
  };
  right_pinky_index_bilateral: homey_right_pinky_index_bilateral {
    compatible = "zmk,behavior-hold-tap";
    flavor = RIGHT_PINKY_HOLDING_TYPE;
    hold-trigger-key-positions = <LEFT_HAND_KEYS THUMB_KEYS>;
    hold-trigger-on-release; // wait for other home row mods
    tapping-term-ms = <RIGHT_PINKY_HOLDING_TIME>;
    require-prior-idle-ms = <RIGHT_PINKY_STREAK_DECAY>;
    #binding-cells = <2>;
    bindings = <&kp>, <&right_pinky_tap>;
  };
  #define RightPinkyIndex right_pinky_index_bilateral RIGHT_INDEX_MOD RIGHT_INDEX_KEY
  #ifndef RIGHT_RINGY_INDEX_HOLDING_TYPE
  #define RIGHT_RINGY_INDEX_HOLDING_TYPE RIGHT_RINGY_CHORD_HOLDING_TYPE
  #endif
  #ifndef RIGHT_RINGY_INDEX_HOLDING_TIME
  #define RIGHT_RINGY_INDEX_HOLDING_TIME RIGHT_RINGY_CHORD_HOLDING_TIME
  #endif
  #ifndef RIGHT_RINGY_INDEX_STREAK_DECAY
  #define RIGHT_RINGY_INDEX_STREAK_DECAY RIGHT_RINGY_CHORD_STREAK_DECAY
  #endif
  right_ringy_index: homey_right_ringy_index {
    compatible = "zmk,behavior-hold-tap";
    flavor = RIGHT_RINGY_HOLDING_TYPE;
    hold-trigger-key-positions = <LEFT_HAND_KEYS THUMB_KEYS>;
    hold-trigger-on-release; // wait for other home row mods
    tapping-term-ms = <RIGHT_RINGY_HOLDING_TIME>;
    require-prior-idle-ms = <RIGHT_RINGY_STREAK_DECAY>;
    #binding-cells = <2>;
    bindings = <&kp>, <&kp>;
  };
  right_ringy_index_bilateral: homey_right_ringy_index_bilateral {
    compatible = "zmk,behavior-hold-tap";
    flavor = RIGHT_RINGY_HOLDING_TYPE;
    hold-trigger-key-positions = <LEFT_HAND_KEYS THUMB_KEYS>;
    hold-trigger-on-release; // wait for other home row mods
    tapping-term-ms = <RIGHT_RINGY_HOLDING_TIME>;
    require-prior-idle-ms = <RIGHT_RINGY_STREAK_DECAY>;
    #binding-cells = <2>;
    bindings = <&kp>, <&right_ringy_tap>;
  };
  #define RightRingyIndex right_ringy_index_bilateral RIGHT_INDEX_MOD RIGHT_INDEX_KEY
  #ifndef RIGHT_MIDDY_INDEX_HOLDING_TYPE
  #define RIGHT_MIDDY_INDEX_HOLDING_TYPE RIGHT_MIDDY_CHORD_HOLDING_TYPE
  #endif
  #ifndef RIGHT_MIDDY_INDEX_HOLDING_TIME
  #define RIGHT_MIDDY_INDEX_HOLDING_TIME RIGHT_MIDDY_CHORD_HOLDING_TIME
  #endif
  #ifndef RIGHT_MIDDY_INDEX_STREAK_DECAY
  #define RIGHT_MIDDY_INDEX_STREAK_DECAY RIGHT_MIDDY_CHORD_STREAK_DECAY
  #endif
  right_middy_index: homey_right_middy_index {
    compatible = "zmk,behavior-hold-tap";
    flavor = RIGHT_MIDDY_HOLDING_TYPE;
    hold-trigger-key-positions = <LEFT_HAND_KEYS THUMB_KEYS>;
    hold-trigger-on-release; // wait for other home row mods
    tapping-term-ms = <RIGHT_MIDDY_HOLDING_TIME>;
    require-prior-idle-ms = <RIGHT_MIDDY_STREAK_DECAY>;
    #binding-cells = <2>;
    bindings = <&kp>, <&kp>;
  };
  right_middy_index_bilateral: homey_right_middy_index_bilateral {
    compatible = "zmk,behavior-hold-tap";
    flavor = RIGHT_MIDDY_HOLDING_TYPE;
    hold-trigger-key-positions = <LEFT_HAND_KEYS THUMB_KEYS>;
    hold-trigger-on-release; // wait for other home row mods
    tapping-term-ms = <RIGHT_MIDDY_HOLDING_TIME>;
    require-prior-idle-ms = <RIGHT_MIDDY_STREAK_DECAY>;
    #binding-cells = <2>;
    bindings = <&kp>, <&right_middy_tap>;
  };
  #define RightMiddyIndex right_middy_index_bilateral RIGHT_INDEX_MOD RIGHT_INDEX_KEY

  //
  // Key repetition access keys on the index fingers
  //
  plain: plain_typing_layer {
    compatible = "zmk,behavior-hold-tap";
    flavor = PLAIN_HOLDING_TYPE;
    tapping-term-ms = <PLAIN_HOLDING_TIME>;
    require-prior-idle-ms = <PLAIN_STREAK_DECAY>;
    #binding-cells = <2>;
    bindings = <&mo>, <&kp>;
    retro-tap; // tap on standalone hold
  };

  //
  // Thumb cluster hold-tap keys for Miryoku layers
  //
  thumb: thumb_layer_access {
    compatible = "zmk,behavior-hold-tap";
    flavor = THUMB_HOLDING_TYPE;
    tapping-term-ms = <THUMB_HOLDING_TIME>;
    #binding-cells = <2>;
    bindings = <&mo>, <&kp>;
  };
  thumb_parang_left: thumb_layer_access_parang_left {
    compatible = "zmk,behavior-hold-tap";
    flavor = THUMB_HOLDING_TYPE;
    tapping-term-ms = <THUMB_HOLDING_TIME>;
    #binding-cells = <2>;
    bindings = <&mo>, <&parang_left>;
  };
  stumb: thumb_layer_access_sticky_key_oneshot {
    compatible = "zmk,behavior-hold-tap";
    flavor = THUMB_HOLDING_TYPE;
    tapping-term-ms = <THUMB_HOLDING_TIME>;
    #binding-cells = <2>;
    bindings = <&mo>, <&sticky_key_oneshot>;
  };
  crumb: thumb_layer_access_retro_tap {
    compatible = "zmk,behavior-hold-tap";
    flavor = THUMB_HOLDING_TYPE;
    tapping-term-ms = <THUMB_HOLDING_TIME>;
    #binding-cells = <2>;
    bindings = <&mo>, <&kp>;
    #ifdef THUMB_FORGIVENESS
    retro-tap;
    #endif
  };
  space: thumb_layer_access_spacebar {
    compatible = "zmk,behavior-hold-tap";
    flavor = SPACE_HOLDING_TYPE;
    tapping-term-ms = <SPACE_HOLDING_TIME>;
    #binding-cells = <2>;
    bindings = <&mo>, <&kp>;
    #ifdef SPACE_FORGIVENESS
    retro-tap; // tap on standalone hold
    #endif
  };

  //
  // Shift + LEFT_PARENTHESIS = LESS_THAN
  //
  parang_left: left_parenthesis_and_less_than {
    compatible = "zmk,behavior-mod-morph";
    #binding-cells = <0>;
    bindings = <&kp LPAR>, <&kp LT>;
    mods = <(MOD_LSFT|MOD_RSFT)>;
  };

  //
  // Shift + RIGHT_PARENTHESIS = GREATER_THAN
  //
  parang_right: right_parenthesis_and_greater_than {
    compatible = "zmk,behavior-mod-morph";
    #binding-cells = <0>;
    bindings = <&kp RPAR>, <&kp GT>;
    mods = <(MOD_LSFT|MOD_RSFT)>;
  };

  //////////////////////////////////////////////////////////////////////////
  //
  // &sk (sticky key) variant that is truly one-shot
  //
  //////////////////////////////////////////////////////////////////////////

  //
  // STICKY_1SHOT_DECAY defines how much time you have left (milliseconds)
  // after tapping a sticky key before it expires (won't apply to next tap).
  //
  #ifndef STICKY_1SHOT_DECAY
  #define STICKY_1SHOT_DECAY 500
  #endif

  //
  // STICKY_HOLDING_TIME defines how long you need to hold (milliseconds)
  // sticky one-shot keys in order to trigger their hold (not tap) action.
  //
  #ifndef STICKY_HOLDING_TIME
  #define STICKY_HOLDING_TIME (TAPPING_RESOLUTION + 50)
  #endif

  sticky_key_modtap: sticky_key_modtap {
    compatible = "zmk,behavior-hold-tap";
    flavor = "tap-preferred";
    tapping-term-ms = <STICKY_HOLDING_TIME>;
    #binding-cells = <2>;
    bindings = <&kp>, <&sticky_key_oneshot>;
  };
  sticky_key_oneshot: sticky_key_oneshot_macro {
    compatible = "zmk,behavior-macro-one-param";
    wait-ms = <0>;
    tap-ms = <0>;
    #binding-cells = <1>;
    bindings
      = <&macro_param_1to1>
      , <&macro_tap &sticky_key_quickrel MACRO_PLACEHOLDER>
      ;
  };
  sticky_key_quickrel: sticky_key_quick_release {
    compatible = "zmk,behavior-sticky-key";
    #binding-cells = <1>;
    bindings = <&kp>;
    release-after-ms = <STICKY_1SHOT_DECAY>;
    quick-release;
    ignore-modifiers;
  };

  //////////////////////////////////////////////////////////////////////////
  //
  // ZMK global overrides
  //
  //////////////////////////////////////////////////////////////////////////

  //
  // CapsWord - ported from Pascal Getreuer's extension for QMK
  // - https://zmk.dev/docs/behaviors/caps-word
  // - https://getreuer.info/posts/keyboards/caps-word/index.html
  //
  behavior_caps_word {
    continue-list = <
      UNDERSCORE MINUS
      BACKSPACE DELETE
      N1 N2 N3 N4 N5 N6 N7 N8 N9 N0
    >;
  };

};

macros {

  //
  // Linux Magic System Request Key - hold this down and type REISUB
  // - https://www.kernel.org/doc/html/latest/admin-guide/sysrq.html
  // - https://github.com/manna-harbour/miryoku/discussions/259
  //
  ZMK_MACRO(linux_magic_sysrq,
    wait-ms = <0>;
    tap-ms = <0>;
    bindings
      = <&macro_press &mo 0 &kp RALT>
      , <&macro_tap &kp PRINTSCREEN>
      , <&macro_pause_for_release>
      , <&macro_release &mo 0 &kp RALT>
      ;
  )

  //
  // Mod+Tab application switcher - hold this down to keep menu open
  //
  mod_tab: mod_tab_switcher {
    compatible = "zmk,behavior-macro-one-param";
    wait-ms = <0>;
    tap-ms = <0>;
    #binding-cells = <1>;
    bindings
      = <&macro_param_1to1>
      , <&macro_press &kp MACRO_PLACEHOLDER>
      , <&macro_tap &kp TAB>
      , <&macro_pause_for_release>
      , <&macro_param_1to1>
      , <&macro_release &kp MACRO_PLACEHOLDER>
      ;
  };
  mod_tab_chord: mod_tab_switcher_chord {
    compatible = "zmk,behavior-macro-two-param";
    wait-ms = <0>;
    tap-ms = <0>;
    #binding-cells = <2>;
    bindings
      = <&macro_param_2to1>
      , <&macro_press &mo MACRO_PLACEHOLDER>
      , <&macro_param_1to1>
      , <&macro_press &mod_tab MACRO_PLACEHOLDER>
      , <&macro_pause_for_release>
      , <&macro_param_1to1>
      , <&macro_release &mod_tab MACRO_PLACEHOLDER>
      , <&macro_param_2to1>
      , <&macro_release &mo MACRO_PLACEHOLDER>
      ;
  };

  //////////////////////////////////////////////////////////////////////////
  //
  // Approximation of Pascal Getreuer's Select Word macro from QMK
  // - https://getreuer.info/posts/keyboards/select-word/index.html
  //
  //////////////////////////////////////////////////////////////////////////

  //
  // SELECT_WORD_DELAY defines how long the macro waits (milliseconds)
  // after moving the cursor before it selects a word.  A larger delay
  // may allow the macro to move to the next word upon each invocation.
  //
  #ifndef SELECT_WORD_DELAY
  #define SELECT_WORD_DELAY 1
  #endif

  #define select_all kp _C(A)

  ZMK_MACRO(select_none,
    wait-ms = <SELECT_WORD_DELAY>;
    tap-ms = <SELECT_WORD_DELAY>;
    bindings = <&kp DOWN &kp UP &kp RIGHT &kp LEFT>;
  )

  //
  // select a word (jumps to next word upon each successive invocation)
  //
  select_word: select_word {
    compatible = "zmk,behavior-mod-morph";
    #binding-cells = <0>;
    bindings = <&select_word_right>, <&select_word_left>;
    mods = <(MOD_LSFT|MOD_RSFT)>;
  };
  ZMK_MACRO(select_word_right,
    wait-ms = <SELECT_WORD_DELAY>;
    tap-ms = <SELECT_WORD_DELAY>;
    bindings = <&kp _W(RIGHT) &kp _W(LEFT) &kp _W(LS(RIGHT))>;
  )
  ZMK_MACRO(select_word_left,
    wait-ms = <SELECT_WORD_DELAY>;
    tap-ms = <SELECT_WORD_DELAY>;
    bindings = <&kp _W(LEFT) &kp _W(RIGHT) &kp _W(LS(LEFT))>;
  )

  //
  // extend current selection by one word
  //
  extend_word: extend_word {
    compatible = "zmk,behavior-mod-morph";
    #binding-cells = <0>;
    bindings = <&extend_word_right>, <&extend_word_left>;
    mods = <(MOD_LSFT|MOD_RSFT)>;
  };
  ZMK_MACRO(extend_word_right,
    wait-ms = <SELECT_WORD_DELAY>;
    tap-ms = <SELECT_WORD_DELAY>;
    bindings = <&kp _W(LS(RIGHT))>;
  )
  ZMK_MACRO(extend_word_left,
    wait-ms = <SELECT_WORD_DELAY>;
    tap-ms = <SELECT_WORD_DELAY>;
    bindings = <&kp _W(LS(LEFT))>;
  )

  //
  // select current line
  //
  select_line: select_line {
    compatible = "zmk,behavior-mod-morph";
    #binding-cells = <0>;
    bindings = <&select_line_right>, <&select_line_left>;
    mods = <(MOD_LSFT|MOD_RSFT)>;
  };
  ZMK_MACRO(select_line_right,
    wait-ms = <SELECT_WORD_DELAY>;
    tap-ms = <SELECT_WORD_DELAY>;
    bindings = <&kp _HOME &kp LS(_END)>;
  )
  ZMK_MACRO(select_line_left,
    wait-ms = <SELECT_WORD_DELAY>;
    tap-ms = <SELECT_WORD_DELAY>;
    bindings = <&kp _END &kp LS(_HOME)>;
  )

  //
  // extend current selection by one line
  //
  extend_line: extend_line {
    compatible = "zmk,behavior-mod-morph";
    #binding-cells = <0>;
    bindings = <&extend_line_right>, <&extend_line_left>;
    mods = <(MOD_LSFT|MOD_RSFT)>;
  };
  ZMK_MACRO(extend_line_right,
    wait-ms = <SELECT_WORD_DELAY>;
    tap-ms = <SELECT_WORD_DELAY>;
    bindings = <&kp LS(DOWN) &kp LS(_END)>;
  )
  ZMK_MACRO(extend_line_left,
    wait-ms = <SELECT_WORD_DELAY>;
    tap-ms = <SELECT_WORD_DELAY>;
    bindings = <&kp LS(UP) &kp LS(_HOME)>;
  )
};
};

/{

};

/* Automatically generated macro definitions */
/ {
    macros {

    };
};

/* Automatically generated behavior definitions */
/ {
    behaviors {
    
    };
};

/* Automatically generated combos definitions */


/* Automatically generated keymap */
/ {
    keymap {
        compatible = "zmk,keymap";

        layer_ColemakDH {
            bindings = <
                       &kp UP                         &kp DOWN                            &kp A                            &kp B                            &kp C                                                                                                                                                                                  &kp D                             &kp E                             &kp F                          &kp LEFT                     &kp RIGHT
                    &kp EQUAL                           &kp N1                           &kp N2                           &kp N3                           &kp N4  &kp N5                                                                                                                                       &kp N6                            &kp N7                            &kp N8                            &kp N9                            &kp N0                     &kp MINUS
                    &kp GRAVE                            &kp Q                            &kp W                            &kp F                            &kp P   &kp B                                                                                                                                        &kp J                             &kp L                             &kp U                             &kp Y                          &kp SEMI                      &kp BSLH
                     &kp CAPS  &LeftPinky (A, LAYER_ColemakDH)  &LeftRingy (R, LAYER_ColemakDH)  &LeftMiddy (S, LAYER_ColemakDH)  &LeftIndex (T, LAYER_ColemakDH)   &kp G                                                                                                                                        &kp M  &RightIndex (N, LAYER_ColemakDH)  &RightMiddy (E, LAYER_ColemakDH)  &RightRingy (I, LAYER_ColemakDH)  &RightPinky (O, LAYER_ColemakDH)                       &kp SQT
 &sticky_key_modtap LSFT LSFT                            &kp Z                            &kp X                            &kp C                            &kp D   &kp V                          &none                       &none       &none    &none                     &none                      &none   &kp K                             &kp H                         &kp COMMA                           &kp DOT                          &kp FSLH                         &none
         &magic LAYER_Magic 0                         &kp HOME                        &kp PG_UP                        &kp PG_DN                            &none          &thumb LAYER_Number BACKSPACE     &thumb LAYER_System ESC  &caps_word  &kp TAB  &thumb LAYER_Mouse ENTER  &space LAYER_Symbol SPACE                                     &none                          &kp LBKT                          &kp RBKT                     &parang_right                         &none
            >;
        };


        layer_LeftPinky {
            bindings = <
 &left_pinky_tap KEY_LH_C6R1  &left_pinky_tap KEY_LH_C5R1  &left_pinky_tap KEY_LH_C4R1  &left_pinky_tap KEY_LH_C3R1  &left_pinky_tap KEY_LH_C2R1                                                                                                    &trans               &trans               &trans               &trans  &trans
 &left_pinky_tap KEY_LH_C6R2  &left_pinky_tap KEY_LH_C5R2  &left_pinky_tap KEY_LH_C4R2  &left_pinky_tap KEY_LH_C3R2  &left_pinky_tap KEY_LH_C2R2  &left_pinky_tap KEY_LH_C1R2                                                  &trans               &trans               &trans               &trans               &trans  &trans
 &left_pinky_tap KEY_LH_C6R3  &left_pinky_tap KEY_LH_C5R3  &left_pinky_tap KEY_LH_C4R3  &left_pinky_tap KEY_LH_C3R3  &left_pinky_tap KEY_LH_C2R3  &left_pinky_tap KEY_LH_C1R3                                                  &trans               &trans               &trans               &trans               &trans  &trans
 &left_pinky_tap KEY_LH_C6R4                        &none              &LeftPinkyRingy              &LeftPinkyMiddy              &LeftPinkyIndex  &left_pinky_tap KEY_LH_C1R4                                                  &trans  &kp RIGHT_INDEX_KEY  &kp RIGHT_MIDDY_KEY  &kp RIGHT_RINGY_KEY  &kp RIGHT_PINKY_KEY  &trans
                      &trans  &left_pinky_tap KEY_LH_C5R5  &left_pinky_tap KEY_LH_C4R5  &left_pinky_tap KEY_LH_C3R5  &left_pinky_tap KEY_LH_C2R5  &left_pinky_tap KEY_LH_C1R5  &trans  &trans  &trans  &trans  &trans  &trans  &trans               &trans               &trans               &trans               &trans  &trans
                      &trans  &left_pinky_tap KEY_LH_C5R6  &left_pinky_tap KEY_LH_C4R6  &left_pinky_tap KEY_LH_C3R6  &left_pinky_tap KEY_LH_C2R6                               &trans  &trans  &trans  &trans  &trans  &trans                       &trans               &trans               &trans               &trans  &trans
            >;
        };

        layer_LeftRingy {
            bindings = <
 &left_ringy_tap KEY_LH_C6R1  &left_ringy_tap KEY_LH_C5R1  &left_ringy_tap KEY_LH_C4R1  &left_ringy_tap KEY_LH_C3R1  &left_ringy_tap KEY_LH_C2R1                                                                                                    &trans               &trans               &trans               &trans  &trans
 &left_ringy_tap KEY_LH_C6R2  &left_ringy_tap KEY_LH_C5R2  &left_ringy_tap KEY_LH_C4R2  &left_ringy_tap KEY_LH_C3R2  &left_ringy_tap KEY_LH_C2R2  &left_ringy_tap KEY_LH_C1R2                                                  &trans               &trans               &trans               &trans               &trans  &trans
 &left_ringy_tap KEY_LH_C6R3  &left_ringy_tap KEY_LH_C5R3  &left_ringy_tap KEY_LH_C4R3  &left_ringy_tap KEY_LH_C3R3  &left_ringy_tap KEY_LH_C2R3  &left_ringy_tap KEY_LH_C1R3                                                  &trans               &trans               &trans               &trans               &trans  &trans
 &left_ringy_tap KEY_LH_C6R4              &LeftRingyPinky                        &none              &LeftRingyMiddy              &LeftRingyIndex  &left_ringy_tap KEY_LH_C1R4                                                  &trans  &kp RIGHT_INDEX_KEY  &kp RIGHT_MIDDY_KEY  &kp RIGHT_RINGY_KEY  &kp RIGHT_PINKY_KEY  &trans
                      &trans  &left_ringy_tap KEY_LH_C5R5  &left_ringy_tap KEY_LH_C4R5  &left_ringy_tap KEY_LH_C3R5  &left_ringy_tap KEY_LH_C2R5  &left_ringy_tap KEY_LH_C1R5  &trans  &trans  &trans  &trans  &trans  &trans  &trans               &trans               &trans               &trans               &trans  &trans
                      &trans  &left_ringy_tap KEY_LH_C5R6  &left_ringy_tap KEY_LH_C4R6  &left_ringy_tap KEY_LH_C3R6  &left_ringy_tap KEY_LH_C2R6                               &trans  &trans  &trans  &trans  &trans  &trans                       &trans               &trans               &trans               &trans  &trans
            >;
        };

        layer_LeftMiddy {
            bindings = <
 &left_middy_tap KEY_LH_C6R1  &left_middy_tap KEY_LH_C5R1  &left_middy_tap KEY_LH_C4R1  &left_middy_tap KEY_LH_C3R1  &left_middy_tap KEY_LH_C2R1                                                                                                    &trans               &trans               &trans               &trans  &trans
 &left_middy_tap KEY_LH_C6R2  &left_middy_tap KEY_LH_C5R2  &left_middy_tap KEY_LH_C4R2  &left_middy_tap KEY_LH_C3R2  &left_middy_tap KEY_LH_C2R2  &left_middy_tap KEY_LH_C1R2                                                  &trans               &trans               &trans               &trans               &trans  &trans
 &left_middy_tap KEY_LH_C6R3  &left_middy_tap KEY_LH_C5R3  &left_middy_tap KEY_LH_C4R3  &left_middy_tap KEY_LH_C3R3  &left_middy_tap KEY_LH_C2R3  &left_middy_tap KEY_LH_C1R3                                                  &trans               &trans               &trans               &trans               &trans  &trans
 &left_middy_tap KEY_LH_C6R4              &LeftMiddyPinky              &LeftMiddyRingy                        &none              &LeftMiddyIndex  &left_middy_tap KEY_LH_C1R4                                                  &trans  &kp RIGHT_INDEX_KEY  &kp RIGHT_MIDDY_KEY  &kp RIGHT_RINGY_KEY  &kp RIGHT_PINKY_KEY  &trans
                      &trans  &left_middy_tap KEY_LH_C5R5  &left_middy_tap KEY_LH_C4R5  &left_middy_tap KEY_LH_C3R5  &left_middy_tap KEY_LH_C2R5  &left_middy_tap KEY_LH_C1R5  &trans  &trans  &trans  &trans  &trans  &trans  &trans               &trans               &trans               &trans               &trans  &trans
                      &trans  &left_middy_tap KEY_LH_C5R6  &left_middy_tap KEY_LH_C4R6  &left_middy_tap KEY_LH_C3R6  &left_middy_tap KEY_LH_C2R6                               &trans  &trans  &trans  &trans  &trans  &trans                       &trans               &trans               &trans               &trans  &trans
            >;
        };

        layer_LeftIndex {
            bindings = <
 &left_index_tap KEY_LH_C6R1  &left_index_tap KEY_LH_C5R1  &left_index_tap KEY_LH_C4R1  &left_index_tap KEY_LH_C3R1  &left_index_tap KEY_LH_C2R1                                                                                                    &trans               &trans               &trans               &trans  &trans
 &left_index_tap KEY_LH_C6R2  &left_index_tap KEY_LH_C5R2  &left_index_tap KEY_LH_C4R2  &left_index_tap KEY_LH_C3R2  &left_index_tap KEY_LH_C2R2  &left_index_tap KEY_LH_C1R2                                                  &trans               &trans               &trans               &trans               &trans  &trans
 &left_index_tap KEY_LH_C6R3  &left_index_tap KEY_LH_C5R3  &left_index_tap KEY_LH_C4R3  &left_index_tap KEY_LH_C3R3  &left_index_tap KEY_LH_C2R3  &left_index_tap KEY_LH_C1R3                                                  &trans               &trans               &trans               &trans               &trans  &trans
 &left_index_tap KEY_LH_C6R4              &LeftIndexPinky              &LeftIndexRingy              &LeftIndexMiddy                        &none  &left_index_tap KEY_LH_C1R4                                                  &trans  &kp RIGHT_INDEX_KEY  &kp RIGHT_MIDDY_KEY  &kp RIGHT_RINGY_KEY  &kp RIGHT_PINKY_KEY  &trans
                      &trans  &left_index_tap KEY_LH_C5R5  &left_index_tap KEY_LH_C4R5  &left_index_tap KEY_LH_C3R5  &left_index_tap KEY_LH_C2R5  &left_index_tap KEY_LH_C1R5  &trans  &trans  &trans  &trans  &trans  &trans  &trans               &trans               &trans               &trans               &trans  &trans
                      &trans  &left_index_tap KEY_LH_C5R6  &left_index_tap KEY_LH_C4R6  &left_index_tap KEY_LH_C3R6  &left_index_tap KEY_LH_C2R6                               &trans  &trans  &trans  &trans  &trans  &trans                       &trans               &trans               &trans               &trans  &trans
            >;
        };

        layer_RightPinky {
            bindings = <
 &trans              &trans              &trans              &trans              &trans                                                                                        &right_pinky_tap KEY_RH_C2R1  &right_pinky_tap KEY_RH_C3R1  &right_pinky_tap KEY_RH_C4R1  &right_pinky_tap KEY_RH_C5R1  &right_pinky_tap KEY_RH_C6R1
 &trans              &trans              &trans              &trans              &trans  &trans                                                  &right_pinky_tap KEY_RH_C1R2  &right_pinky_tap KEY_RH_C2R2  &right_pinky_tap KEY_RH_C3R2  &right_pinky_tap KEY_RH_C4R2  &right_pinky_tap KEY_RH_C5R2  &right_pinky_tap KEY_RH_C6R2
 &trans              &trans              &trans              &trans              &trans  &trans                                                  &right_pinky_tap KEY_RH_C1R3  &right_pinky_tap KEY_RH_C2R3  &right_pinky_tap KEY_RH_C3R3  &right_pinky_tap KEY_RH_C4R3  &right_pinky_tap KEY_RH_C5R3  &right_pinky_tap KEY_RH_C6R3
 &trans  &kp LEFT_PINKY_KEY  &kp LEFT_RINGY_KEY  &kp LEFT_MIDDY_KEY  &kp LEFT_INDEX_KEY  &trans                                                  &right_pinky_tap KEY_RH_C1R4              &RightPinkyIndex              &RightPinkyMiddy              &RightPinkyRingy                         &none  &right_pinky_tap KEY_RH_C6R4
 &trans              &trans              &trans              &trans              &trans  &trans  &trans  &trans  &trans  &trans  &trans  &trans  &right_pinky_tap KEY_RH_C1R5  &right_pinky_tap KEY_RH_C2R5  &right_pinky_tap KEY_RH_C3R5  &right_pinky_tap KEY_RH_C4R5  &right_pinky_tap KEY_RH_C5R5                        &trans
 &trans              &trans              &trans              &trans              &trans          &trans  &trans  &trans  &trans  &trans  &trans                                &right_pinky_tap KEY_RH_C2R6  &right_pinky_tap KEY_RH_C3R6  &right_pinky_tap KEY_RH_C4R6  &right_pinky_tap KEY_RH_C5R6                        &trans
            >;
        };

        layer_RightRingy {
            bindings = <
 &trans              &trans              &trans              &trans              &trans                                                                                        &right_ringy_tap KEY_RH_C2R1  &right_ringy_tap KEY_RH_C3R1  &right_ringy_tap KEY_RH_C4R1  &right_ringy_tap KEY_RH_C5R1  &right_ringy_tap KEY_RH_C6R1
 &trans              &trans              &trans              &trans              &trans  &trans                                                  &right_ringy_tap KEY_RH_C1R2  &right_ringy_tap KEY_RH_C2R2  &right_ringy_tap KEY_RH_C3R2  &right_ringy_tap KEY_RH_C4R2  &right_ringy_tap KEY_RH_C5R2  &right_ringy_tap KEY_RH_C6R2
 &trans              &trans              &trans              &trans              &trans  &trans                                                  &right_ringy_tap KEY_RH_C1R3  &right_ringy_tap KEY_RH_C2R3  &right_ringy_tap KEY_RH_C3R3  &right_ringy_tap KEY_RH_C4R3  &right_ringy_tap KEY_RH_C5R3  &right_ringy_tap KEY_RH_C6R3
 &trans  &kp LEFT_PINKY_KEY  &kp LEFT_RINGY_KEY  &kp LEFT_MIDDY_KEY  &kp LEFT_INDEX_KEY  &trans                                                  &right_ringy_tap KEY_RH_C1R4              &RightRingyIndex              &RightRingyMiddy                         &none              &RightRingyPinky  &right_ringy_tap KEY_RH_C6R4
 &trans              &trans              &trans              &trans              &trans  &trans  &trans  &trans  &trans  &trans  &trans  &trans  &right_ringy_tap KEY_RH_C1R5  &right_ringy_tap KEY_RH_C2R5  &right_ringy_tap KEY_RH_C3R5  &right_ringy_tap KEY_RH_C4R5  &right_ringy_tap KEY_RH_C5R5                        &trans
 &trans              &trans              &trans              &trans              &trans          &trans  &trans  &trans  &trans  &trans  &trans                                &right_ringy_tap KEY_RH_C2R6  &right_ringy_tap KEY_RH_C3R6  &right_ringy_tap KEY_RH_C4R6  &right_ringy_tap KEY_RH_C5R6                        &trans
            >;
        };

        layer_RightMiddy {
            bindings = <
 &trans              &trans              &trans              &trans              &trans                                                                                        &right_middy_tap KEY_RH_C2R1  &right_middy_tap KEY_RH_C3R1  &right_middy_tap KEY_RH_C4R1  &right_middy_tap KEY_RH_C5R1  &right_middy_tap KEY_RH_C6R1
 &trans              &trans              &trans              &trans              &trans  &trans                                                  &right_middy_tap KEY_RH_C1R2  &right_middy_tap KEY_RH_C2R2  &right_middy_tap KEY_RH_C3R2  &right_middy_tap KEY_RH_C4R2  &right_middy_tap KEY_RH_C5R2  &right_middy_tap KEY_RH_C6R2
 &trans              &trans              &trans              &trans              &trans  &trans                                                  &right_middy_tap KEY_RH_C1R3  &right_middy_tap KEY_RH_C2R3  &right_middy_tap KEY_RH_C3R3  &right_middy_tap KEY_RH_C4R3  &right_middy_tap KEY_RH_C5R3  &right_middy_tap KEY_RH_C6R3
 &trans  &kp LEFT_PINKY_KEY  &kp LEFT_RINGY_KEY  &kp LEFT_MIDDY_KEY  &kp LEFT_INDEX_KEY  &trans                                                  &right_middy_tap KEY_RH_C1R4              &RightMiddyIndex                         &none              &RightMiddyRingy              &RightMiddyPinky  &right_middy_tap KEY_RH_C6R4
 &trans              &trans              &trans              &trans              &trans  &trans  &trans  &trans  &trans  &trans  &trans  &trans  &right_middy_tap KEY_RH_C1R5  &right_middy_tap KEY_RH_C2R5  &right_middy_tap KEY_RH_C3R5  &right_middy_tap KEY_RH_C4R5  &right_middy_tap KEY_RH_C5R5                        &trans
 &trans              &trans              &trans              &trans              &trans          &trans  &trans  &trans  &trans  &trans  &trans                                &right_middy_tap KEY_RH_C2R6  &right_middy_tap KEY_RH_C3R6  &right_middy_tap KEY_RH_C4R6  &right_middy_tap KEY_RH_C5R6                        &trans
            >;
        };

        layer_RightIndex {
            bindings = <
 &trans              &trans              &trans              &trans              &trans                                                                                        &right_index_tap KEY_RH_C2R1  &right_index_tap KEY_RH_C3R1  &right_index_tap KEY_RH_C4R1  &right_index_tap KEY_RH_C5R1  &right_index_tap KEY_RH_C6R1
 &trans              &trans              &trans              &trans              &trans  &trans                                                  &right_index_tap KEY_RH_C1R2  &right_index_tap KEY_RH_C2R2  &right_index_tap KEY_RH_C3R2  &right_index_tap KEY_RH_C4R2  &right_index_tap KEY_RH_C5R2  &right_index_tap KEY_RH_C6R2
 &trans              &trans              &trans              &trans              &trans  &trans                                                  &right_index_tap KEY_RH_C1R3  &right_index_tap KEY_RH_C2R3  &right_index_tap KEY_RH_C3R3  &right_index_tap KEY_RH_C4R3  &right_index_tap KEY_RH_C5R3  &right_index_tap KEY_RH_C6R3
 &trans  &kp LEFT_PINKY_KEY  &kp LEFT_RINGY_KEY  &kp LEFT_MIDDY_KEY  &kp LEFT_INDEX_KEY  &trans                                                  &right_index_tap KEY_RH_C1R4                         &none              &RightIndexMiddy              &RightIndexRingy              &RightIndexPinky  &right_index_tap KEY_RH_C6R4
 &trans              &trans              &trans              &trans              &trans  &trans  &trans  &trans  &trans  &trans  &trans  &trans  &right_index_tap KEY_RH_C1R5  &right_index_tap KEY_RH_C2R5  &right_index_tap KEY_RH_C3R5  &right_index_tap KEY_RH_C4R5  &right_index_tap KEY_RH_C5R5                        &trans
 &trans              &trans              &trans              &trans              &trans          &trans  &trans  &trans  &trans  &trans  &trans                                &right_index_tap KEY_RH_C2R6  &right_index_tap KEY_RH_C3R6  &right_index_tap KEY_RH_C4R6  &right_index_tap KEY_RH_C5R6                        &trans
            >;
        };

        layer_Number {
            bindings = <
   &none               &none               &none               &none               &none                                                                                                             &none         &none          &none          &none             &none
 &kp ESC             &kp RET           &kp SPACE             &kp TAB             &kp DEL  &kp INS                                                                                    &kp TILDE   &kp CARET      &kp HASH       &kp DLLR       &kp EXCL            &kp AT
   &kp A           &sk LSHFT           &kp _REDO           &kp _UNDO            &kp BSPC    &kp D                                                                                     &kp STAR      &kp N7        &kp N8         &kp N9      &kp EQUAL         &kp PRCNT
   &kp B            &kp LGUI            &kp LALT           &kp LCTRL           &kp LSHFT    &kp E                                                                                    &kp MINUS      &kp N4        &kp N5         &kp N6       &kp PLUS          &kp PLUS
   &kp C         &select_all        &select_line        &select_word               &kp X    &kp F       &none   &none  &tog LAYER_Number         &kp LT       &kp GT  &kp EQUAL      &kp UNDER      &kp N1        &kp N2         &kp N3       &kp BSLH      &kp ASTERISK
   &none               &none        &extend_line        &extend_word           &kp UNDER           &kp KP_NUM   &none              &none  &kp _KP_COMMA  &kp _KP_DOT     &kp N0                   &kp LBKT        &kp N0  &parang_right       &kp RBKT          &kp PIPE
            >;
        };

        layer_Symbol {
            bindings = <
     &none      &none      &none      &none     &none                                                                                                        &none                &none                &none                &none        &none
     &none      &none      &none      &none     &none      &none                                                                        &none  &sk RIGHT_INDEX_MOD  &sk RIGHT_MIDDY_MOD  &sk RIGHT_RINGY_MOD  &sk RIGHT_PINKY_MOD        &none
 &kp GRAVE   &kp EXCL     &kp AT   &kp LBRC  &kp RBRC  &kp GRAVE                                                                     &kp HOME             &kp LEFT               &kp UP             &kp DOWN            &kp RIGHT      &kp END
  &kp EXCL   &kp HASH  &kp CARET   &kp LPAR  &kp RPAR   &kp DLLR                                                                      &kp DQT             &kp BSPC              &kp TAB            &kp SPACE              &kp RET    &kp GRAVE
  &kp HASH  &kp PRCNT   &kp AMPS   &kp LBKT  &kp RBKT  &kp TILDE   &none   &none   &kp SQT              &kp DEL          &kp LS(TAB)         &select_word         &select_line  &select_all
     &none   &kp AMPS    &kp SQT    &kp DQT  &kp PLUS             &kp PRCNT  &kp COLON    &kp AT              &none   &none   &none                      &kp _UNDO            &kp _REDO         &extend_word         &extend_line        &none
            >;
        };

        layer_Mouse {
            bindings = <
  &none           &none           &none           &none            &none                                                                                                   &none                &none                &none                &none   &none
  &none           &none           &none           &none            &none   &none                                                                      &none  &sk RIGHT_INDEX_MOD  &sk RIGHT_MIDDY_MOD  &sk RIGHT_RINGY_MOD  &sk RIGHT_PINKY_MOD   &none
  &none           &none  &msc SCRL_LEFT    &mmv MOVE_UP  &msc SCRL_RIGHT   &none                                                                  &mkp MCLK  &kp RIGHT_INDEX_MOD  &kp RIGHT_MIDDY_MOD  &kp RIGHT_RINGY_MOD  &kp RIGHT_PINKY_MOD   &none
  &none    &msc SCRL_UP  &mmv MOVE_LEFT  &mmv MOVE_DOWN  &mmv MOVE_RIGHT   &none                                                                  &mkp LCLK       &mmv MOVE_LEFT         &mmv MOVE_UP       &mmv MOVE_DOWN      &mmv MOVE_RIGHT   &none
  &none  &msc SCRL_DOWN           &none           &none            &none   &none  &mkp MCLK      &none   &none  &tog LAYER_Mouse   &none   &none  &mkp RCLK       &msc SCRL_LEFT         &msc SCRL_UP       &msc SCRL_DOWN      &msc SCRL_RIGHT   &none
  &none           &none           &none           &none            &none          &mkp LCLK  &mkp RCLK   &none             &none   &none   &none                           &none                &none                &none                &none   &none
            >;
        };

        layer_System {
            bindings = <
  &none            &none            &none            &none               &none                                                                                                                          &none                &none                &none                &none            &none
  &none            &none            &none            &none               &none            &none                                                                                    &none  &sk RIGHT_INDEX_MOD  &sk RIGHT_MIDDY_MOD  &sk RIGHT_RINGY_MOD  &sk RIGHT_PINKY_MOD            &none
  &none            &none  &rgb_ug RGB_HUD  &rgb_ug RGB_HUI     &rgb_ug RGB_TOG  &kp PAUSE_BREAK                                                                             &kp C_BRI_DN         &kp C_VOL_DN         &kp C_VOL_UP         &kp C_BRI_UP            &kp PSCRN           &trans
  &none         &kp LGUI         &kp LALT        &kp LCTRL           &kp LSHFT        &kp PSCRN                                                                                 &kp LEFT             &kp DOWN               &kp UP            &kp RIGHT            &kp PG_UP           &trans
  &none  &rgb_ug RGB_SPD  &rgb_ug RGB_SAD  &rgb_ug RGB_SAI     &rgb_ug RGB_SPI        &kp K_APP  &kp _LOCK  &kp _SLEEP  &kp _POWER  &tog LAYER_System   &none     &none         &kp C_RW           &kp C_NEXT           &kp C_PREV             &kp C_FF            &kp PG_DN           &trans
  &none            &none            &none            &none  &linux_magic_sysrq                    &kp SLCK  &kp KP_NUM    &kp CAPS              &none   &none  &kp C_PP                                 &none      &rgb_ug RGB_BRI      &rgb_ug RGB_BRD                &none            &none
            >;
        };

        layer_Magic {
            bindings = <
  &bt BT_CLR            &none            &none            &none            &none                                                                                  &none   &none   &none   &none  &bt BT_CLR_ALL
       &to 0            &to 1            &to 2            &to 3            &to 4            &to 5                                                         &to 6   &to 7   &to 8   &to 9  &to 10           &none
       &none  &rgb_ug RGB_SPI  &rgb_ug RGB_SAI  &rgb_ug RGB_HUI  &rgb_ug RGB_BRI  &rgb_ug RGB_TOG                                                         &none   &none   &none   &none   &none           &none
 &bootloader  &rgb_ug RGB_SPD  &rgb_ug RGB_SAD  &rgb_ug RGB_HUD  &rgb_ug RGB_BRD  &rgb_ug RGB_EFF                                                         &none   &none   &none   &none   &none     &bootloader
  &sys_reset            &none            &none            &none            &none            &none   &bt_2   &bt_3       &tog 29   &none   &none   &none   &none   &none   &none   &none   &none      &sys_reset
       &none            &none            &none            &none            &none                    &bt_0   &bt_1  &out OUT_USB   &none   &none   &none           &none   &none   &none   &none           &none
            >;
        };

    };
};
